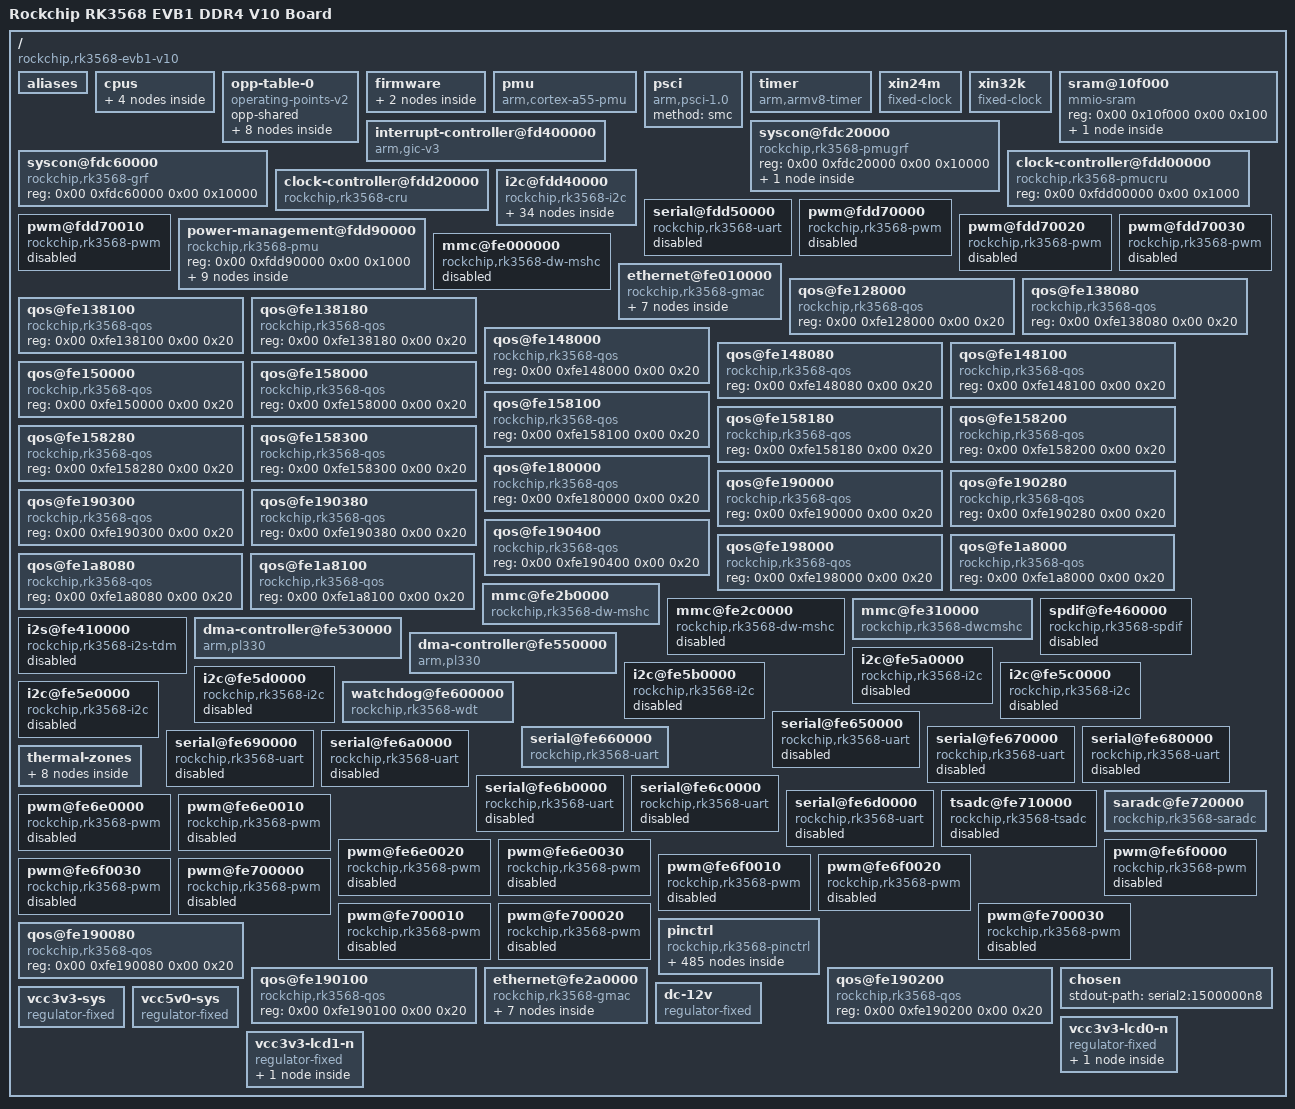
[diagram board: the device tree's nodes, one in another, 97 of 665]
/dts-v1/;

/ {
	interrupt-parent = <0x01>;
	#address-cells = <0x02>;
	#size-cells = <0x02>;
	compatible = "rockchip,rk3568-evb1-v10\0rockchip,rk3568";
	model = "Rockchip RK3568 EVB1 DDR4 V10 Board";

	aliases {
		gpio0 = "/pinctrl/gpio@fdd60000";
		gpio1 = "/pinctrl/gpio@fe740000";
		gpio2 = "/pinctrl/gpio@fe750000";
		gpio3 = "/pinctrl/gpio@fe760000";
		gpio4 = "/pinctrl/gpio@fe770000";
		i2c0 = "/i2c@fdd40000";
		i2c1 = "/i2c@fe5a0000";
		i2c2 = "/i2c@fe5b0000";
		i2c3 = "/i2c@fe5c0000";
		i2c4 = "/i2c@fe5d0000";
		i2c5 = "/i2c@fe5e0000";
		serial0 = "/serial@fdd50000";
		serial1 = "/serial@fe650000";
		serial2 = "/serial@fe660000";
		serial3 = "/serial@fe670000";
		serial4 = "/serial@fe680000";
		serial5 = "/serial@fe690000";
		serial6 = "/serial@fe6a0000";
		serial7 = "/serial@fe6b0000";
		serial8 = "/serial@fe6c0000";
		serial9 = "/serial@fe6d0000";
		ethernet0 = "/ethernet@fe2a0000";
		ethernet1 = "/ethernet@fe010000";
		mmc0 = "/mmc@fe2b0000";
		mmc1 = "/mmc@fe310000";
	};

	cpus {
		#address-cells = <0x02>;
		#size-cells = <0x00>;

		cpu@0 {
			device_type = "cpu";
			compatible = "arm,cortex-a55";
			reg = <0x00 0x00>;
			clocks = <0x02 0x00>;
			#cooling-cells = <0x02>;
			enable-method = "psci";
			operating-points-v2 = <0x03>;
			phandle = <0x05>;
		};

		cpu@100 {
			device_type = "cpu";
			compatible = "arm,cortex-a55";
			reg = <0x00 0x100>;
			#cooling-cells = <0x02>;
			enable-method = "psci";
			operating-points-v2 = <0x03>;
			phandle = <0x06>;
		};

		cpu@200 {
			device_type = "cpu";
			compatible = "arm,cortex-a55";
			reg = <0x00 0x200>;
			#cooling-cells = <0x02>;
			enable-method = "psci";
			operating-points-v2 = <0x03>;
			phandle = <0x07>;
		};

		cpu@300 {
			device_type = "cpu";
			compatible = "arm,cortex-a55";
			reg = <0x00 0x300>;
			#cooling-cells = <0x02>;
			enable-method = "psci";
			operating-points-v2 = <0x03>;
			phandle = <0x08>;
		};
	};

	opp-table-0 {
		compatible = "operating-points-v2";
		opp-shared;
		phandle = <0x03>;

		opp-408000000 {
			opp-hz = <0x00 0x18519600>;
			opp-microvolt = <0xdbba0 0xdbba0 0x118c30>;
			clock-latency-ns = <0x9c40>;
		};

		opp-600000000 {
			opp-hz = <0x00 0x23c34600>;
			opp-microvolt = <0xdbba0 0xdbba0 0x118c30>;
		};

		opp-816000000 {
			opp-hz = <0x00 0x30a32c00>;
			opp-microvolt = <0xdbba0 0xdbba0 0x118c30>;
			opp-suspend;
		};

		opp-1104000000 {
			opp-hz = <0x00 0x41cdb400>;
			opp-microvolt = <0xdbba0 0xdbba0 0x118c30>;
		};

		opp-1416000000 {
			opp-hz = <0x00 0x54667200>;
			opp-microvolt = <0xdbba0 0xdbba0 0x118c30>;
		};

		opp-1608000000 {
			opp-hz = <0x00 0x5fd82200>;
			opp-microvolt = <0xee098 0xee098 0x118c30>;
		};

		opp-1800000000 {
			opp-hz = <0x00 0x6b49d200>;
			opp-microvolt = <0x100590 0x100590 0x118c30>;
		};

		opp-1992000000 {
			opp-hz = <0x00 0x76bb8200>;
			opp-microvolt = <0x118c30 0x118c30 0x118c30>;
		};
	};

	firmware {

		scmi {
			compatible = "arm,scmi-smc";
			arm,smc-id = <0x82000010>;
			shmem = <0x04>;
			#address-cells = <0x01>;
			#size-cells = <0x00>;
			phandle = <0x89>;

			protocol@14 {
				reg = <0x14>;
				#clock-cells = <0x01>;
				phandle = <0x02>;
			};
		};
	};

	pmu {
		compatible = "arm,cortex-a55-pmu";
		interrupts = <0x00 0xe4 0x04 0x00 0xe5 0x04 0x00 0xe6 0x04 0x00 0xe7 0x04>;
		interrupt-affinity = <0x05 0x06 0x07 0x08>;
	};

	psci {
		compatible = "arm,psci-1.0";
		method = "smc";
	};

	timer {
		compatible = "arm,armv8-timer";
		interrupts = <0x01 0x0d 0x04 0x01 0x0e 0x04 0x01 0x0b 0x04 0x01 0x0a 0x04>;
		arm,no-tick-in-suspend;
	};

	xin24m {
		compatible = "fixed-clock";
		clock-frequency = <0x16e3600>;
		clock-output-names = "xin24m";
		#clock-cells = <0x00>;
		phandle = <0x8a>;
	};

	xin32k {
		compatible = "fixed-clock";
		clock-frequency = <0x8000>;
		clock-output-names = "xin32k";
		pinctrl-0 = <0x09>;
		pinctrl-names = "default";
		#clock-cells = <0x00>;
		phandle = <0x8b>;
	};

	sram@10f000 {
		compatible = "mmio-sram";
		reg = <0x00 0x10f000 0x00 0x100>;
		#address-cells = <0x01>;
		#size-cells = <0x01>;
		ranges = <0x00 0x00 0x10f000 0x100>;

		sram@0 {
			compatible = "arm,scmi-shmem";
			reg = <0x00 0x100>;
			phandle = <0x04>;
		};
	};

	interrupt-controller@fd400000 {
		compatible = "arm,gic-v3";
		reg = <0x00 0xfd400000 0x00 0x10000 0x00 0xfd460000 0x00 0x80000>;
		interrupts = <0x01 0x09 0x04>;
		interrupt-controller;
		#interrupt-cells = <0x03>;
		mbi-alias = <0x00 0xfd410000>;
		mbi-ranges = <0x128 0x18>;
		msi-controller;
		phandle = <0x01>;
	};

	syscon@fdc20000 {
		compatible = "rockchip,rk3568-pmugrf\0syscon\0simple-mfd";
		reg = <0x00 0xfdc20000 0x00 0x10000>;
		phandle = <0x76>;

		io-domains {
			compatible = "rockchip,rk3568-pmu-io-voltage-domain";
			status = "okay";
			pmuio1-supply = <0x0a>;
			pmuio2-supply = <0x0a>;
			vccio1-supply = <0x0b>;
			vccio2-supply = <0x0c>;
			vccio3-supply = <0x0d>;
			vccio4-supply = <0x0c>;
			vccio5-supply = <0x0e>;
			vccio6-supply = <0x0c>;
			vccio7-supply = <0x0e>;
			phandle = <0x8c>;
		};
	};

	syscon@fdc60000 {
		compatible = "rockchip,rk3568-grf\0syscon\0simple-mfd";
		reg = <0x00 0xfdc60000 0x00 0x10000>;
		phandle = <0x11>;
	};

	clock-controller@fdd00000 {
		compatible = "rockchip,rk3568-pmucru";
		reg = <0x00 0xfdd00000 0x00 0x1000>;
		#clock-cells = <0x01>;
		#reset-cells = <0x01>;
		phandle = <0x10>;
	};

	clock-controller@fdd20000 {
		compatible = "rockchip,rk3568-cru";
		reg = <0x00 0xfdd20000 0x00 0x1000>;
		#clock-cells = <0x01>;
		#reset-cells = <0x01>;
		assigned-clocks = <0x0f 0x04 0x10 0x01>;
		assigned-clock-rates = <0x47868c00 0xbebc200>;
		rockchip,grf = <0x11>;
		phandle = <0x0f>;
	};

	i2c@fdd40000 {
		compatible = "rockchip,rk3568-i2c\0rockchip,rk3399-i2c";
		reg = <0x00 0xfdd40000 0x00 0x1000>;
		interrupts = <0x00 0x2e 0x04>;
		clocks = <0x10 0x07 0x10 0x2d>;
		clock-names = "i2c\0pclk";
		pinctrl-0 = <0x12>;
		pinctrl-names = "default";
		#address-cells = <0x01>;
		#size-cells = <0x00>;
		status = "okay";
		phandle = <0x8d>;

		pmic@20 {
			compatible = "rockchip,rk809";
			reg = <0x20>;
			interrupt-parent = <0x13>;
			interrupts = <0x03 0x08>;
			#clock-cells = <0x01>;
			pinctrl-names = "default";
			pinctrl-0 = <0x14>;
			rockchip,system-power-controller;
			vcc1-supply = <0x15>;
			vcc2-supply = <0x15>;
			vcc3-supply = <0x15>;
			vcc4-supply = <0x15>;
			vcc5-supply = <0x15>;
			vcc6-supply = <0x15>;
			vcc7-supply = <0x15>;
			vcc8-supply = <0x15>;
			vcc9-supply = <0x15>;
			wakeup-source;
			phandle = <0x8e>;

			regulators {

				DCDC_REG1 {
					regulator-name = "vdd_logic";
					regulator-always-on;
					regulator-boot-on;
					regulator-init-microvolt = <0xdbba0>;
					regulator-initial-mode = <0x02>;
					regulator-min-microvolt = <0x7a120>;
					regulator-max-microvolt = <0x149970>;
					regulator-ramp-delay = <0x1771>;
					phandle = <0x8f>;

					regulator-state-mem {
						regulator-off-in-suspend;
					};
				};

				DCDC_REG2 {
					regulator-name = "vdd_gpu";
					regulator-init-microvolt = <0xdbba0>;
					regulator-initial-mode = <0x02>;
					regulator-min-microvolt = <0x7a120>;
					regulator-max-microvolt = <0x149970>;
					regulator-ramp-delay = <0x1771>;
					phandle = <0x90>;

					regulator-state-mem {
						regulator-off-in-suspend;
					};
				};

				DCDC_REG3 {
					regulator-name = "vcc_ddr";
					regulator-always-on;
					regulator-boot-on;
					regulator-initial-mode = <0x02>;
					phandle = <0x91>;

					regulator-state-mem {
						regulator-on-in-suspend;
					};
				};

				DCDC_REG4 {
					regulator-name = "vdd_npu";
					regulator-init-microvolt = <0xdbba0>;
					regulator-initial-mode = <0x02>;
					regulator-min-microvolt = <0x7a120>;
					regulator-max-microvolt = <0x149970>;
					regulator-ramp-delay = <0x1771>;
					phandle = <0x92>;

					regulator-state-mem {
						regulator-off-in-suspend;
					};
				};

				DCDC_REG5 {
					regulator-name = "vcc_1v8";
					regulator-always-on;
					regulator-boot-on;
					regulator-min-microvolt = <0x1b7740>;
					regulator-max-microvolt = <0x1b7740>;
					phandle = <0x0c>;

					regulator-state-mem {
						regulator-off-in-suspend;
					};
				};

				LDO_REG1 {
					regulator-name = "vdda0v9_image";
					regulator-min-microvolt = <0xdbba0>;
					regulator-max-microvolt = <0xdbba0>;
					phandle = <0x93>;

					regulator-state-mem {
						regulator-off-in-suspend;
					};
				};

				LDO_REG2 {
					regulator-name = "vdda_0v9";
					regulator-always-on;
					regulator-boot-on;
					regulator-min-microvolt = <0xdbba0>;
					regulator-max-microvolt = <0xdbba0>;
					phandle = <0x94>;

					regulator-state-mem {
						regulator-off-in-suspend;
					};
				};

				LDO_REG3 {
					regulator-name = "vdda0v9_pmu";
					regulator-always-on;
					regulator-boot-on;
					regulator-min-microvolt = <0xdbba0>;
					regulator-max-microvolt = <0xdbba0>;
					phandle = <0x95>;

					regulator-state-mem {
						regulator-on-in-suspend;
						regulator-suspend-microvolt = <0xdbba0>;
					};
				};

				LDO_REG4 {
					regulator-name = "vccio_acodec";
					regulator-min-microvolt = <0x325aa0>;
					regulator-max-microvolt = <0x325aa0>;
					phandle = <0x0b>;

					regulator-state-mem {
						regulator-off-in-suspend;
					};
				};

				LDO_REG5 {
					regulator-name = "vccio_sd";
					regulator-min-microvolt = <0x1b7740>;
					regulator-max-microvolt = <0x325aa0>;
					phandle = <0x0d>;

					regulator-state-mem {
						regulator-off-in-suspend;
					};
				};

				LDO_REG6 {
					regulator-name = "vcc3v3_pmu";
					regulator-always-on;
					regulator-boot-on;
					regulator-min-microvolt = <0x325aa0>;
					regulator-max-microvolt = <0x325aa0>;
					phandle = <0x0a>;

					regulator-state-mem {
						regulator-on-in-suspend;
						regulator-suspend-microvolt = <0x325aa0>;
					};
				};

				LDO_REG7 {
					regulator-name = "vcca_1v8";
					regulator-always-on;
					regulator-boot-on;
					regulator-min-microvolt = <0x1b7740>;
					regulator-max-microvolt = <0x1b7740>;
					phandle = <0x69>;

					regulator-state-mem {
						regulator-off-in-suspend;
					};
				};

				LDO_REG8 {
					regulator-name = "vcca1v8_pmu";
					regulator-always-on;
					regulator-boot-on;
					regulator-min-microvolt = <0x1b7740>;
					regulator-max-microvolt = <0x1b7740>;
					phandle = <0x96>;

					regulator-state-mem {
						regulator-on-in-suspend;
						regulator-suspend-microvolt = <0x1b7740>;
					};
				};

				LDO_REG9 {
					regulator-name = "vcca1v8_image";
					regulator-min-microvolt = <0x1b7740>;
					regulator-max-microvolt = <0x1b7740>;
					phandle = <0x97>;

					regulator-state-mem {
						regulator-off-in-suspend;
					};
				};

				SWITCH_REG1 {
					regulator-name = "vcc_3v3";
					regulator-always-on;
					regulator-boot-on;
					phandle = <0x0e>;

					regulator-state-mem {
						regulator-off-in-suspend;
					};
				};

				SWITCH_REG2 {
					regulator-name = "vcc3v3_sd";
					phandle = <0x44>;

					regulator-state-mem {
						regulator-off-in-suspend;
					};
				};
			};
		};
	};

	serial@fdd50000 {
		compatible = "rockchip,rk3568-uart\0snps,dw-apb-uart";
		reg = <0x00 0xfdd50000 0x00 0x100>;
		interrupts = <0x00 0x74 0x04>;
		clocks = <0x10 0x0b 0x10 0x2c>;
		clock-names = "baudclk\0apb_pclk";
		dmas = <0x16 0x00 0x16 0x01>;
		pinctrl-0 = <0x17>;
		pinctrl-names = "default";
		reg-io-width = <0x04>;
		reg-shift = <0x02>;
		status = "disabled";
		phandle = <0x98>;
	};

	pwm@fdd70000 {
		compatible = "rockchip,rk3568-pwm\0rockchip,rk3328-pwm";
		reg = <0x00 0xfdd70000 0x00 0x10>;
		clocks = <0x10 0x0d 0x10 0x30>;
		clock-names = "pwm\0pclk";
		pinctrl-0 = <0x18>;
		pinctrl-names = "active";
		#pwm-cells = <0x03>;
		status = "disabled";
		phandle = <0x99>;
	};

	pwm@fdd70010 {
		compatible = "rockchip,rk3568-pwm\0rockchip,rk3328-pwm";
		reg = <0x00 0xfdd70010 0x00 0x10>;
		clocks = <0x10 0x0d 0x10 0x30>;
		clock-names = "pwm\0pclk";
		pinctrl-0 = <0x19>;
		pinctrl-names = "active";
		#pwm-cells = <0x03>;
		status = "disabled";
		phandle = <0x9a>;
	};

	pwm@fdd70020 {
		compatible = "rockchip,rk3568-pwm\0rockchip,rk3328-pwm";
		reg = <0x00 0xfdd70020 0x00 0x10>;
		clocks = <0x10 0x0d 0x10 0x30>;
		clock-names = "pwm\0pclk";
		pinctrl-0 = <0x1a>;
		pinctrl-names = "active";
		#pwm-cells = <0x03>;
		status = "disabled";
		phandle = <0x9b>;
	};

	pwm@fdd70030 {
		compatible = "rockchip,rk3568-pwm\0rockchip,rk3328-pwm";
		reg = <0x00 0xfdd70030 0x00 0x10>;
		clocks = <0x10 0x0d 0x10 0x30>;
		clock-names = "pwm\0pclk";
		pinctrl-0 = <0x1b>;
		pinctrl-names = "active";
		#pwm-cells = <0x03>;
		status = "disabled";
		phandle = <0x9c>;
	};

	power-management@fdd90000 {
		compatible = "rockchip,rk3568-pmu\0syscon\0simple-mfd";
		reg = <0x00 0xfdd90000 0x00 0x1000>;
		phandle = <0x9d>;

		power-controller {
			compatible = "rockchip,rk3568-power-controller";
			#power-domain-cells = <0x01>;
			#address-cells = <0x01>;
			#size-cells = <0x00>;
			phandle = <0x9e>;

			power-domain@7 {
				reg = <0x07>;
				clocks = <0x0f 0x19 0x0f 0x1a>;
				pm_qos = <0x1c>;
				#power-domain-cells = <0x00>;
			};

			power-domain@8 {
				reg = <0x08>;
				clocks = <0x0f 0xcc 0x0f 0xcd>;
				pm_qos = <0x1d 0x1e 0x1f>;
				#power-domain-cells = <0x00>;
			};

			power-domain@9 {
				reg = <0x09>;
				clocks = <0x0f 0xda 0x0f 0xdb 0x0f 0xdc>;
				pm_qos = <0x20 0x21 0x22>;
				#power-domain-cells = <0x00>;
			};

			power-domain@10 {
				reg = <0x0a>;
				clocks = <0x0f 0xf1 0x0f 0xf2>;
				pm_qos = <0x23 0x24 0x25 0x26 0x27 0x28>;
				#power-domain-cells = <0x00>;
			};

			power-domain@11 {
				reg = <0x0b>;
				clocks = <0x0f 0xed>;
				pm_qos = <0x29>;
				#power-domain-cells = <0x00>;
			};

			power-domain@13 {
				clocks = <0x0f 0x107>;
				reg = <0x0d>;
				pm_qos = <0x2a>;
				#power-domain-cells = <0x00>;
			};

			power-domain@14 {
				reg = <0x0e>;
				clocks = <0x0f 0x102>;
				pm_qos = <0x2b 0x2c 0x2d>;
				#power-domain-cells = <0x00>;
			};

			power-domain@15 {
				reg = <0x0f>;
				clocks = <0x0f 0x7f>;
				pm_qos = <0x2e 0x2f 0x30 0x31 0x32 0x33 0x34 0x35>;
				#power-domain-cells = <0x00>;
			};
		};
	};

	mmc@fe000000 {
		compatible = "rockchip,rk3568-dw-mshc\0rockchip,rk3288-dw-mshc";
		reg = <0x00 0xfe000000 0x00 0x4000>;
		interrupts = <0x00 0x64 0x04>;
		clocks = <0x0f 0xc1 0x0f 0xc2 0x0f 0x18e 0x0f 0x18f>;
		clock-names = "biu\0ciu\0ciu-drive\0ciu-sample";
		fifo-depth = <0x100>;
		max-frequency = <0x8f0d180>;
		resets = <0x0f 0xeb>;
		reset-names = "reset";
		status = "disabled";
		phandle = <0x9f>;
	};

	ethernet@fe010000 {
		compatible = "rockchip,rk3568-gmac\0snps,dwmac-4.20a";
		reg = <0x00 0xfe010000 0x00 0x10000>;
		interrupts = <0x00 0x20 0x04 0x00 0x1d 0x04>;
		interrupt-names = "macirq\0eth_wake_irq";
		clocks = <0x0f 0x186 0x0f 0x189 0x0f 0x189 0x0f 0xc7 0x0f 0xc3 0x0f 0xc4 0x0f 0x189 0x0f 0xc8>;
		clock-names = "stmmaceth\0mac_clk_rx\0mac_clk_tx\0clk_mac_refout\0aclk_mac\0pclk_mac\0clk_mac_speed\0ptp_ref";
		resets = <0x0f 0xec>;
		reset-names = "stmmaceth";
		rockchip,grf = <0x11>;
		snps,axi-config = <0x36>;
		snps,mixed-burst;
		snps,mtl-rx-config = <0x37>;
		snps,mtl-tx-config = <0x38>;
		snps,tso;
		status = "okay";
		assigned-clocks = <0x0f 0x189 0x0f 0x186>;
		assigned-clock-parents = <0x0f 0x187>;
		assigned-clock-rates = <0x00 0x7735940>;
		clock_in_out = "output";
		phy-handle = <0x39>;
		phy-mode = "rgmii-id";
		pinctrl-names = "default";
		pinctrl-0 = <0x3a 0x3b 0x3c 0x3d 0x3e>;
		phandle = <0xa0>;

		mdio {
			compatible = "snps,dwmac-mdio";
			#address-cells = <0x01>;
			#size-cells = <0x00>;
			phandle = <0xa1>;

			ethernet-phy@0 {
				compatible = "ethernet-phy-ieee802.3-c22";
				reg = <0x00>;
				reset-assert-us = <0x4e20>;
				reset-deassert-us = <0x186a0>;
				reset-gpios = <0x3f 0x19 0x01>;
				phandle = <0x39>;
			};
		};

		stmmac-axi-config {
			snps,blen = <0x00 0x00 0x00 0x00 0x10 0x08 0x04>;
			snps,rd_osr_lmt = <0x08>;
			snps,wr_osr_lmt = <0x04>;
			phandle = <0x36>;
		};

		rx-queues-config {
			snps,rx-queues-to-use = <0x01>;
			phandle = <0x37>;

			queue0 {
			};
		};

		tx-queues-config {
			snps,tx-queues-to-use = <0x01>;
			phandle = <0x38>;

			queue0 {
			};
		};
	};

	qos@fe128000 {
		compatible = "rockchip,rk3568-qos\0syscon";
		reg = <0x00 0xfe128000 0x00 0x20>;
		phandle = <0x1c>;
	};

	qos@fe138080 {
		compatible = "rockchip,rk3568-qos\0syscon";
		reg = <0x00 0xfe138080 0x00 0x20>;
		phandle = <0x2b>;
	};

	qos@fe138100 {
		compatible = "rockchip,rk3568-qos\0syscon";
		reg = <0x00 0xfe138100 0x00 0x20>;
		phandle = <0x2c>;
	};

	qos@fe138180 {
		compatible = "rockchip,rk3568-qos\0syscon";
		reg = <0x00 0xfe138180 0x00 0x20>;
		phandle = <0x2d>;
	};

	qos@fe148000 {
		compatible = "rockchip,rk3568-qos\0syscon";
		reg = <0x00 0xfe148000 0x00 0x20>;
		phandle = <0x1d>;
	};

	qos@fe148080 {
		compatible = "rockchip,rk3568-qos\0syscon";
		reg = <0x00 0xfe148080 0x00 0x20>;
		phandle = <0x1e>;
	};

	qos@fe148100 {
		compatible = "rockchip,rk3568-qos\0syscon";
		reg = <0x00 0xfe148100 0x00 0x20>;
		phandle = <0x1f>;
	};

	qos@fe150000 {
		compatible = "rockchip,rk3568-qos\0syscon";
		reg = <0x00 0xfe150000 0x00 0x20>;
		phandle = <0x29>;
	};

	qos@fe158000 {
		compatible = "rockchip,rk3568-qos\0syscon";
		reg = <0x00 0xfe158000 0x00 0x20>;
		phandle = <0x23>;
	};

	qos@fe158100 {
		compatible = "rockchip,rk3568-qos\0syscon";
		reg = <0x00 0xfe158100 0x00 0x20>;
		phandle = <0x24>;
	};

	qos@fe158180 {
		compatible = "rockchip,rk3568-qos\0syscon";
		reg = <0x00 0xfe158180 0x00 0x20>;
		phandle = <0x25>;
	};

	qos@fe158200 {
		compatible = "rockchip,rk3568-qos\0syscon";
		reg = <0x00 0xfe158200 0x00 0x20>;
		phandle = <0x26>;
	};

	qos@fe158280 {
		compatible = "rockchip,rk3568-qos\0syscon";
		reg = <0x00 0xfe158280 0x00 0x20>;
		phandle = <0x27>;
	};

	qos@fe158300 {
		compatible = "rockchip,rk3568-qos\0syscon";
		reg = <0x00 0xfe158300 0x00 0x20>;
		phandle = <0x28>;
	};

	qos@fe180000 {
		compatible = "rockchip,rk3568-qos\0syscon";
		reg = <0x00 0xfe180000 0x00 0x20>;
		phandle = <0xa2>;
	};

	qos@fe190000 {
		compatible = "rockchip,rk3568-qos\0syscon";
		reg = <0x00 0xfe190000 0x00 0x20>;
		phandle = <0x2e>;
	};

	qos@fe190280 {
		compatible = "rockchip,rk3568-qos\0syscon";
		reg = <0x00 0xfe190280 0x00 0x20>;
		phandle = <0x32>;
	};

	qos@fe190300 {
		compatible = "rockchip,rk3568-qos\0syscon";
		reg = <0x00 0xfe190300 0x00 0x20>;
		phandle = <0x33>;
	};

	qos@fe190380 {
		compatible = "rockchip,rk3568-qos\0syscon";
		reg = <0x00 0xfe190380 0x00 0x20>;
		phandle = <0x34>;
	};

	qos@fe190400 {
		compatible = "rockchip,rk3568-qos\0syscon";
		reg = <0x00 0xfe190400 0x00 0x20>;
		phandle = <0x35>;
	};

	qos@fe198000 {
		compatible = "rockchip,rk3568-qos\0syscon";
		reg = <0x00 0xfe198000 0x00 0x20>;
		phandle = <0x2a>;
	};

	qos@fe1a8000 {
		compatible = "rockchip,rk3568-qos\0syscon";
		reg = <0x00 0xfe1a8000 0x00 0x20>;
		phandle = <0x20>;
	};

	qos@fe1a8080 {
		compatible = "rockchip,rk3568-qos\0syscon";
		reg = <0x00 0xfe1a8080 0x00 0x20>;
		phandle = <0x21>;
	};

	qos@fe1a8100 {
		compatible = "rockchip,rk3568-qos\0syscon";
		reg = <0x00 0xfe1a8100 0x00 0x20>;
		phandle = <0x22>;
	};

	mmc@fe2b0000 {
		compatible = "rockchip,rk3568-dw-mshc\0rockchip,rk3288-dw-mshc";
		reg = <0x00 0xfe2b0000 0x00 0x4000>;
		interrupts = <0x00 0x62 0x04>;
		clocks = <0x0f 0xb0 0x0f 0xb1 0x0f 0x18a 0x0f 0x18b>;
		clock-names = "biu\0ciu\0ciu-drive\0ciu-sample";
		fifo-depth = <0x100>;
		max-frequency = <0x8f0d180>;
		resets = <0x0f 0xd4>;
		reset-names = "reset";
		status = "okay";
		bus-width = <0x04>;
		cap-sd-highspeed;
		cd-gpios = <0x13 0x04 0x01>;
		disable-wp;
		pinctrl-names = "default";
		pinctrl-0 = <0x40 0x41 0x42 0x43>;
		sd-uhs-sdr104;
		vmmc-supply = <0x44>;
		vqmmc-supply = <0x0d>;
		phandle = <0xa3>;
	};

	mmc@fe2c0000 {
		compatible = "rockchip,rk3568-dw-mshc\0rockchip,rk3288-dw-mshc";
		reg = <0x00 0xfe2c0000 0x00 0x4000>;
		interrupts = <0x00 0x63 0x04>;
		clocks = <0x0f 0xb2 0x0f 0xb3 0x0f 0x18c 0x0f 0x18d>;
		clock-names = "biu\0ciu\0ciu-drive\0ciu-sample";
		fifo-depth = <0x100>;
		max-frequency = <0x8f0d180>;
		resets = <0x0f 0xd6>;
		reset-names = "reset";
		status = "disabled";
		phandle = <0xa4>;
	};

	mmc@fe310000 {
		compatible = "rockchip,rk3568-dwcmshc";
		reg = <0x00 0xfe310000 0x00 0x10000>;
		interrupts = <0x00 0x13 0x04>;
		assigned-clocks = <0x0f 0x7b 0x0f 0x7d>;
		assigned-clock-rates = <0xbebc200 0x16e3600>;
		clocks = <0x0f 0x7c 0x0f 0x7a 0x0f 0x79 0x0f 0x7b 0x0f 0x7d>;
		clock-names = "core\0bus\0axi\0block\0timer";
		status = "okay";
		bus-width = <0x08>;
		max-frequency = <0xbebc200>;
		non-removable;
		pinctrl-names = "default";
		pinctrl-0 = <0x45 0x46 0x47 0x48>;
		phandle = <0xa5>;
	};

	spdif@fe460000 {
		compatible = "rockchip,rk3568-spdif";
		reg = <0x00 0xfe460000 0x00 0x1000>;
		interrupts = <0x00 0x66 0x04>;
		clock-names = "mclk\0hclk";
		clocks = <0x0f 0x5f 0x0f 0x5c>;
		dmas = <0x49 0x01>;
		dma-names = "tx";
		pinctrl-names = "default";
		pinctrl-0 = <0x4a>;
		#sound-dai-cells = <0x00>;
		status = "disabled";
		phandle = <0xa6>;
	};

	i2s@fe410000 {
		compatible = "rockchip,rk3568-i2s-tdm";
		reg = <0x00 0xfe410000 0x00 0x1000>;
		interrupts = <0x00 0x35 0x04>;
		assigned-clocks = <0x0f 0x45 0x0f 0x49>;
		assigned-clock-rates = <0x46cf7100 0x46cf7100>;
		clocks = <0x0f 0x47 0x0f 0x4b 0x0f 0x3a>;
		clock-names = "mclk_tx\0mclk_rx\0hclk";
		dmas = <0x49 0x03 0x49 0x02>;
		dma-names = "rx\0tx";
		resets = <0x0f 0x52 0x0f 0x53>;
		reset-names = "tx-m\0rx-m";
		rockchip,grf = <0x11>;
		pinctrl-names = "default";
		pinctrl-0 = <0x4b 0x4c 0x4d 0x4e 0x4f 0x50 0x51 0x52 0x53 0x54 0x55 0x56>;
		#sound-dai-cells = <0x00>;
		status = "disabled";
		phandle = <0xa7>;
	};

	dma-controller@fe530000 {
		compatible = "arm,pl330\0arm,primecell";
		reg = <0x00 0xfe530000 0x00 0x4000>;
		interrupts = <0x00 0x0e 0x04 0x00 0x0d 0x04>;
		arm,pl330-periph-burst;
		clocks = <0x0f 0x10d>;
		clock-names = "apb_pclk";
		#dma-cells = <0x01>;
		phandle = <0x16>;
	};

	dma-controller@fe550000 {
		compatible = "arm,pl330\0arm,primecell";
		reg = <0x00 0xfe550000 0x00 0x4000>;
		interrupts = <0x00 0x10 0x04 0x00 0x0f 0x04>;
		arm,pl330-periph-burst;
		clocks = <0x0f 0x10d>;
		clock-names = "apb_pclk";
		#dma-cells = <0x01>;
		phandle = <0x49>;
	};

	i2c@fe5a0000 {
		compatible = "rockchip,rk3568-i2c\0rockchip,rk3399-i2c";
		reg = <0x00 0xfe5a0000 0x00 0x1000>;
		interrupts = <0x00 0x2f 0x04>;
		clocks = <0x0f 0x148 0x0f 0x147>;
		clock-names = "i2c\0pclk";
		pinctrl-0 = <0x57>;
		pinctrl-names = "default";
		#address-cells = <0x01>;
		#size-cells = <0x00>;
		status = "disabled";
		phandle = <0xa8>;
	};

	i2c@fe5b0000 {
		compatible = "rockchip,rk3568-i2c\0rockchip,rk3399-i2c";
		reg = <0x00 0xfe5b0000 0x00 0x1000>;
		interrupts = <0x00 0x30 0x04>;
		clocks = <0x0f 0x14a 0x0f 0x149>;
		clock-names = "i2c\0pclk";
		pinctrl-0 = <0x58>;
		pinctrl-names = "default";
		#address-cells = <0x01>;
		#size-cells = <0x00>;
		status = "disabled";
		phandle = <0xa9>;
	};

	i2c@fe5c0000 {
		compatible = "rockchip,rk3568-i2c\0rockchip,rk3399-i2c";
		reg = <0x00 0xfe5c0000 0x00 0x1000>;
		interrupts = <0x00 0x31 0x04>;
		clocks = <0x0f 0x14c 0x0f 0x14b>;
		clock-names = "i2c\0pclk";
		pinctrl-0 = <0x59>;
		pinctrl-names = "default";
		#address-cells = <0x01>;
		#size-cells = <0x00>;
		status = "disabled";
		phandle = <0xaa>;
	};

	i2c@fe5d0000 {
		compatible = "rockchip,rk3568-i2c\0rockchip,rk3399-i2c";
		reg = <0x00 0xfe5d0000 0x00 0x1000>;
		interrupts = <0x00 0x32 0x04>;
		clocks = <0x0f 0x14e 0x0f 0x14d>;
		clock-names = "i2c\0pclk";
		pinctrl-0 = <0x5a>;
		pinctrl-names = "default";
		#address-cells = <0x01>;
		#size-cells = <0x00>;
		status = "disabled";
		phandle = <0xab>;
	};

	i2c@fe5e0000 {
		compatible = "rockchip,rk3568-i2c\0rockchip,rk3399-i2c";
		reg = <0x00 0xfe5e0000 0x00 0x1000>;
		interrupts = <0x00 0x33 0x04>;
		clocks = <0x0f 0x150 0x0f 0x14f>;
		clock-names = "i2c\0pclk";
		pinctrl-0 = <0x5b>;
		pinctrl-names = "default";
		#address-cells = <0x01>;
		#size-cells = <0x00>;
		status = "disabled";
		phandle = <0xac>;
	};

	watchdog@fe600000 {
		compatible = "rockchip,rk3568-wdt\0snps,dw-wdt";
		reg = <0x00 0xfe600000 0x00 0x100>;
		interrupts = <0x00 0x95 0x04>;
		clocks = <0x0f 0x116 0x0f 0x115>;
		clock-names = "tclk\0pclk";
		phandle = <0xad>;
	};

	serial@fe650000 {
		compatible = "rockchip,rk3568-uart\0snps,dw-apb-uart";
		reg = <0x00 0xfe650000 0x00 0x100>;
		interrupts = <0x00 0x75 0x04>;
		clocks = <0x0f 0x11f 0x0f 0x11c>;
		clock-names = "baudclk\0apb_pclk";
		dmas = <0x16 0x02 0x16 0x03>;
		pinctrl-0 = <0x5c>;
		pinctrl-names = "default";
		reg-io-width = <0x04>;
		reg-shift = <0x02>;
		status = "disabled";
		phandle = <0xae>;
	};

	serial@fe660000 {
		compatible = "rockchip,rk3568-uart\0snps,dw-apb-uart";
		reg = <0x00 0xfe660000 0x00 0x100>;
		interrupts = <0x00 0x76 0x04>;
		clocks = <0x0f 0x123 0x0f 0x120>;
		clock-names = "baudclk\0apb_pclk";
		dmas = <0x16 0x04 0x16 0x05>;
		pinctrl-0 = <0x5d>;
		pinctrl-names = "default";
		reg-io-width = <0x04>;
		reg-shift = <0x02>;
		status = "okay";
		phandle = <0xaf>;
	};

	serial@fe670000 {
		compatible = "rockchip,rk3568-uart\0snps,dw-apb-uart";
		reg = <0x00 0xfe670000 0x00 0x100>;
		interrupts = <0x00 0x77 0x04>;
		clocks = <0x0f 0x127 0x0f 0x124>;
		clock-names = "baudclk\0apb_pclk";
		dmas = <0x16 0x06 0x16 0x07>;
		pinctrl-0 = <0x5e>;
		pinctrl-names = "default";
		reg-io-width = <0x04>;
		reg-shift = <0x02>;
		status = "disabled";
		phandle = <0xb0>;
	};

	serial@fe680000 {
		compatible = "rockchip,rk3568-uart\0snps,dw-apb-uart";
		reg = <0x00 0xfe680000 0x00 0x100>;
		interrupts = <0x00 0x78 0x04>;
		clocks = <0x0f 0x12b 0x0f 0x128>;
		clock-names = "baudclk\0apb_pclk";
		dmas = <0x16 0x08 0x16 0x09>;
		pinctrl-0 = <0x5f>;
		pinctrl-names = "default";
		reg-io-width = <0x04>;
		reg-shift = <0x02>;
		status = "disabled";
		phandle = <0xb1>;
	};

	serial@fe690000 {
		compatible = "rockchip,rk3568-uart\0snps,dw-apb-uart";
		reg = <0x00 0xfe690000 0x00 0x100>;
		interrupts = <0x00 0x79 0x04>;
		clocks = <0x0f 0x12f 0x0f 0x12c>;
		clock-names = "baudclk\0apb_pclk";
		dmas = <0x16 0x0a 0x16 0x0b>;
		pinctrl-0 = <0x60>;
		pinctrl-names = "default";
		reg-io-width = <0x04>;
		reg-shift = <0x02>;
		status = "disabled";
		phandle = <0xb2>;
	};

	serial@fe6a0000 {
		compatible = "rockchip,rk3568-uart\0snps,dw-apb-uart";
		reg = <0x00 0xfe6a0000 0x00 0x100>;
		interrupts = <0x00 0x7a 0x04>;
		clocks = <0x0f 0x133 0x0f 0x130>;
		clock-names = "baudclk\0apb_pclk";
		dmas = <0x16 0x0c 0x16 0x0d>;
		pinctrl-0 = <0x61>;
		pinctrl-names = "default";
		reg-io-width = <0x04>;
		reg-shift = <0x02>;
		status = "disabled";
		phandle = <0xb3>;
	};

	serial@fe6b0000 {
		compatible = "rockchip,rk3568-uart\0snps,dw-apb-uart";
		reg = <0x00 0xfe6b0000 0x00 0x100>;
		interrupts = <0x00 0x7b 0x04>;
		clocks = <0x0f 0x137 0x0f 0x134>;
		clock-names = "baudclk\0apb_pclk";
		dmas = <0x16 0x0e 0x16 0x0f>;
		pinctrl-0 = <0x62>;
		pinctrl-names = "default";
		reg-io-width = <0x04>;
		reg-shift = <0x02>;
		status = "disabled";
		phandle = <0xb4>;
	};

	serial@fe6c0000 {
		compatible = "rockchip,rk3568-uart\0snps,dw-apb-uart";
		reg = <0x00 0xfe6c0000 0x00 0x100>;
		interrupts = <0x00 0x7c 0x04>;
		clocks = <0x0f 0x13b 0x0f 0x138>;
		clock-names = "baudclk\0apb_pclk";
		dmas = <0x16 0x10 0x16 0x11>;
		pinctrl-0 = <0x63>;
		pinctrl-names = "default";
		reg-io-width = <0x04>;
		reg-shift = <0x02>;
		status = "disabled";
		phandle = <0xb5>;
	};

	serial@fe6d0000 {
		compatible = "rockchip,rk3568-uart\0snps,dw-apb-uart";
		reg = <0x00 0xfe6d0000 0x00 0x100>;
		interrupts = <0x00 0x7d 0x04>;
		clocks = <0x0f 0x13f 0x0f 0x13c>;
		clock-names = "baudclk\0apb_pclk";
		dmas = <0x16 0x12 0x16 0x13>;
		pinctrl-0 = <0x64>;
		pinctrl-names = "default";
		reg-io-width = <0x04>;
		reg-shift = <0x02>;
		status = "disabled";
		phandle = <0xb6>;
	};

	thermal-zones {
		phandle = <0xb7>;

		cpu-thermal {
			polling-delay-passive = <0x64>;
			polling-delay = <0x3e8>;
			thermal-sensors = <0x65 0x00>;
			phandle = <0xb8>;

			trips {

				cpu_alert0 {
					temperature = <0x11170>;
					hysteresis = <0x7d0>;
					type = "passive";
					phandle = <0x66>;
				};

				cpu_alert1 {
					temperature = <0x124f8>;
					hysteresis = <0x7d0>;
					type = "passive";
					phandle = <0xb9>;
				};

				cpu_crit {
					temperature = <0x17318>;
					hysteresis = <0x7d0>;
					type = "critical";
					phandle = <0xba>;
				};
			};

			cooling-maps {

				map0 {
					trip = <0x66>;
					cooling-device = <0x05 0xffffffff 0xffffffff 0x06 0xffffffff 0xffffffff 0x07 0xffffffff 0xffffffff 0x08 0xffffffff 0xffffffff>;
				};
			};
		};

		gpu-thermal {
			polling-delay-passive = <0x14>;
			polling-delay = <0x3e8>;
			thermal-sensors = <0x65 0x01>;
			phandle = <0xbb>;
		};
	};

	tsadc@fe710000 {
		compatible = "rockchip,rk3568-tsadc";
		reg = <0x00 0xfe710000 0x00 0x100>;
		interrupts = <0x00 0x73 0x04>;
		assigned-clocks = <0x0f 0x110 0x0f 0x111>;
		assigned-clock-rates = <0x1036640 0xaae60>;
		clocks = <0x0f 0x111 0x0f 0x10f>;
		clock-names = "tsadc\0apb_pclk";
		resets = <0x0f 0x181 0x0f 0x182 0x0f 0x1d7>;
		rockchip,grf = <0x11>;
		rockchip,hw-tshut-temp = <0x17318>;
		pinctrl-names = "init\0default\0sleep";
		pinctrl-0 = <0x67>;
		pinctrl-1 = <0x68>;
		pinctrl-2 = <0x67>;
		#thermal-sensor-cells = <0x01>;
		status = "disabled";
		phandle = <0x65>;
	};

	saradc@fe720000 {
		compatible = "rockchip,rk3568-saradc\0rockchip,rk3399-saradc";
		reg = <0x00 0xfe720000 0x00 0x100>;
		interrupts = <0x00 0x5d 0x04>;
		clocks = <0x0f 0x113 0x0f 0x112>;
		clock-names = "saradc\0apb_pclk";
		resets = <0x0f 0x180>;
		reset-names = "saradc-apb";
		#io-channel-cells = <0x01>;
		status = "okay";
		vref-supply = <0x69>;
		phandle = <0xbc>;
	};

	pwm@fe6e0000 {
		compatible = "rockchip,rk3568-pwm\0rockchip,rk3328-pwm";
		reg = <0x00 0xfe6e0000 0x00 0x10>;
		clocks = <0x0f 0x15a 0x0f 0x159>;
		clock-names = "pwm\0pclk";
		pinctrl-0 = <0x6a>;
		pinctrl-names = "active";
		#pwm-cells = <0x03>;
		status = "disabled";
		phandle = <0xbd>;
	};

	pwm@fe6e0010 {
		compatible = "rockchip,rk3568-pwm\0rockchip,rk3328-pwm";
		reg = <0x00 0xfe6e0010 0x00 0x10>;
		clocks = <0x0f 0x15a 0x0f 0x159>;
		clock-names = "pwm\0pclk";
		pinctrl-0 = <0x6b>;
		pinctrl-names = "active";
		#pwm-cells = <0x03>;
		status = "disabled";
		phandle = <0xbe>;
	};

	pwm@fe6e0020 {
		compatible = "rockchip,rk3568-pwm\0rockchip,rk3328-pwm";
		reg = <0x00 0xfe6e0020 0x00 0x10>;
		clocks = <0x0f 0x15a 0x0f 0x159>;
		clock-names = "pwm\0pclk";
		pinctrl-0 = <0x6c>;
		pinctrl-names = "active";
		#pwm-cells = <0x03>;
		status = "disabled";
		phandle = <0xbf>;
	};

	pwm@fe6e0030 {
		compatible = "rockchip,rk3568-pwm\0rockchip,rk3328-pwm";
		reg = <0x00 0xfe6e0030 0x00 0x10>;
		clocks = <0x0f 0x15a 0x0f 0x159>;
		clock-names = "pwm\0pclk";
		pinctrl-0 = <0x6d>;
		pinctrl-names = "active";
		#pwm-cells = <0x03>;
		status = "disabled";
		phandle = <0xc0>;
	};

	pwm@fe6f0000 {
		compatible = "rockchip,rk3568-pwm\0rockchip,rk3328-pwm";
		reg = <0x00 0xfe6f0000 0x00 0x10>;
		clocks = <0x0f 0x15d 0x0f 0x15c>;
		clock-names = "pwm\0pclk";
		pinctrl-0 = <0x6e>;
		pinctrl-names = "active";
		#pwm-cells = <0x03>;
		status = "disabled";
		phandle = <0xc1>;
	};

	pwm@fe6f0010 {
		compatible = "rockchip,rk3568-pwm\0rockchip,rk3328-pwm";
		reg = <0x00 0xfe6f0010 0x00 0x10>;
		clocks = <0x0f 0x15d 0x0f 0x15c>;
		clock-names = "pwm\0pclk";
		pinctrl-0 = <0x6f>;
		pinctrl-names = "active";
		#pwm-cells = <0x03>;
		status = "disabled";
		phandle = <0xc2>;
	};

	pwm@fe6f0020 {
		compatible = "rockchip,rk3568-pwm\0rockchip,rk3328-pwm";
		reg = <0x00 0xfe6f0020 0x00 0x10>;
		clocks = <0x0f 0x15d 0x0f 0x15c>;
		clock-names = "pwm\0pclk";
		pinctrl-0 = <0x70>;
		pinctrl-names = "active";
		#pwm-cells = <0x03>;
		status = "disabled";
		phandle = <0xc3>;
	};

	pwm@fe6f0030 {
		compatible = "rockchip,rk3568-pwm\0rockchip,rk3328-pwm";
		reg = <0x00 0xfe6f0030 0x00 0x10>;
		clocks = <0x0f 0x15d 0x0f 0x15c>;
		clock-names = "pwm\0pclk";
		pinctrl-0 = <0x71>;
		pinctrl-names = "active";
		#pwm-cells = <0x03>;
		status = "disabled";
		phandle = <0xc4>;
	};

	pwm@fe700000 {
		compatible = "rockchip,rk3568-pwm\0rockchip,rk3328-pwm";
		reg = <0x00 0xfe700000 0x00 0x10>;
		clocks = <0x0f 0x160 0x0f 0x15f>;
		clock-names = "pwm\0pclk";
		pinctrl-0 = <0x72>;
		pinctrl-names = "active";
		#pwm-cells = <0x03>;
		status = "disabled";
		phandle = <0xc5>;
	};

	pwm@fe700010 {
		compatible = "rockchip,rk3568-pwm\0rockchip,rk3328-pwm";
		reg = <0x00 0xfe700010 0x00 0x10>;
		clocks = <0x0f 0x160 0x0f 0x15f>;
		clock-names = "pwm\0pclk";
		pinctrl-0 = <0x73>;
		pinctrl-names = "active";
		#pwm-cells = <0x03>;
		status = "disabled";
		phandle = <0xc6>;
	};

	pwm@fe700020 {
		compatible = "rockchip,rk3568-pwm\0rockchip,rk3328-pwm";
		reg = <0x00 0xfe700020 0x00 0x10>;
		clocks = <0x0f 0x160 0x0f 0x15f>;
		clock-names = "pwm\0pclk";
		pinctrl-0 = <0x74>;
		pinctrl-names = "active";
		#pwm-cells = <0x03>;
		status = "disabled";
		phandle = <0xc7>;
	};

	pwm@fe700030 {
		compatible = "rockchip,rk3568-pwm\0rockchip,rk3328-pwm";
		reg = <0x00 0xfe700030 0x00 0x10>;
		clocks = <0x0f 0x160 0x0f 0x15f>;
		clock-names = "pwm\0pclk";
		pinctrl-0 = <0x75>;
		pinctrl-names = "active";
		#pwm-cells = <0x03>;
		status = "disabled";
		phandle = <0xc8>;
	};

	pinctrl {
		compatible = "rockchip,rk3568-pinctrl";
		rockchip,grf = <0x11>;
		rockchip,pmu = <0x76>;
		#address-cells = <0x02>;
		#size-cells = <0x02>;
		ranges;
		phandle = <0xc9>;

		gpio@fdd60000 {
			compatible = "rockchip,gpio-bank";
			reg = <0x00 0xfdd60000 0x00 0x100>;
			interrupts = <0x00 0x21 0x04>;
			clocks = <0x10 0x2e 0x10 0x0c>;
			gpio-controller;
			#gpio-cells = <0x02>;
			interrupt-controller;
			#interrupt-cells = <0x02>;
			phandle = <0x13>;
		};

		gpio@fe740000 {
			compatible = "rockchip,gpio-bank";
			reg = <0x00 0xfe740000 0x00 0x100>;
			interrupts = <0x00 0x22 0x04>;
			clocks = <0x0f 0x163 0x0f 0x164>;
			gpio-controller;
			#gpio-cells = <0x02>;
			interrupt-controller;
			#interrupt-cells = <0x02>;
			phandle = <0xca>;
		};

		gpio@fe750000 {
			compatible = "rockchip,gpio-bank";
			reg = <0x00 0xfe750000 0x00 0x100>;
			interrupts = <0x00 0x23 0x04>;
			clocks = <0x0f 0x165 0x0f 0x166>;
			gpio-controller;
			#gpio-cells = <0x02>;
			interrupt-controller;
			#interrupt-cells = <0x02>;
			phandle = <0x3f>;
		};

		gpio@fe760000 {
			compatible = "rockchip,gpio-bank";
			reg = <0x00 0xfe760000 0x00 0x100>;
			interrupts = <0x00 0x24 0x04>;
			clocks = <0x0f 0x167 0x0f 0x168>;
			gpio-controller;
			#gpio-cells = <0x02>;
			interrupt-controller;
			#interrupt-cells = <0x02>;
			phandle = <0xcb>;
		};

		gpio@fe770000 {
			compatible = "rockchip,gpio-bank";
			reg = <0x00 0xfe770000 0x00 0x100>;
			interrupts = <0x00 0x25 0x04>;
			clocks = <0x0f 0x169 0x0f 0x16a>;
			gpio-controller;
			#gpio-cells = <0x02>;
			interrupt-controller;
			#interrupt-cells = <0x02>;
			phandle = <0xcc>;
		};

		pcfg-pull-up {
			bias-pull-up;
			phandle = <0x79>;
		};

		pcfg-pull-down {
			bias-pull-down;
			phandle = <0xcd>;
		};

		pcfg-pull-none {
			bias-disable;
			phandle = <0x77>;
		};

		pcfg-pull-none-drv-level-0 {
			bias-disable;
			drive-strength = <0x00>;
			phandle = <0xce>;
		};

		pcfg-pull-none-drv-level-1 {
			bias-disable;
			drive-strength = <0x01>;
			phandle = <0x7b>;
		};

		pcfg-pull-none-drv-level-2 {
			bias-disable;
			drive-strength = <0x02>;
			phandle = <0x7a>;
		};

		pcfg-pull-none-drv-level-3 {
			bias-disable;
			drive-strength = <0x03>;
			phandle = <0x7e>;
		};

		pcfg-pull-none-drv-level-4 {
			bias-disable;
			drive-strength = <0x04>;
			phandle = <0xcf>;
		};

		pcfg-pull-none-drv-level-5 {
			bias-disable;
			drive-strength = <0x05>;
			phandle = <0xd0>;
		};

		pcfg-pull-none-drv-level-6 {
			bias-disable;
			drive-strength = <0x06>;
			phandle = <0xd1>;
		};

		pcfg-pull-none-drv-level-7 {
			bias-disable;
			drive-strength = <0x07>;
			phandle = <0xd2>;
		};

		pcfg-pull-none-drv-level-8 {
			bias-disable;
			drive-strength = <0x08>;
			phandle = <0xd3>;
		};

		pcfg-pull-none-drv-level-9 {
			bias-disable;
			drive-strength = <0x09>;
			phandle = <0xd4>;
		};

		pcfg-pull-none-drv-level-10 {
			bias-disable;
			drive-strength = <0x0a>;
			phandle = <0xd5>;
		};

		pcfg-pull-none-drv-level-11 {
			bias-disable;
			drive-strength = <0x0b>;
			phandle = <0xd6>;
		};

		pcfg-pull-none-drv-level-12 {
			bias-disable;
			drive-strength = <0x0c>;
			phandle = <0xd7>;
		};

		pcfg-pull-none-drv-level-13 {
			bias-disable;
			drive-strength = <0x0d>;
			phandle = <0xd8>;
		};

		pcfg-pull-none-drv-level-14 {
			bias-disable;
			drive-strength = <0x0e>;
			phandle = <0xd9>;
		};

		pcfg-pull-none-drv-level-15 {
			bias-disable;
			drive-strength = <0x0f>;
			phandle = <0xda>;
		};

		pcfg-pull-up-drv-level-0 {
			bias-pull-up;
			drive-strength = <0x00>;
			phandle = <0xdb>;
		};

		pcfg-pull-up-drv-level-1 {
			bias-pull-up;
			drive-strength = <0x01>;
			phandle = <0x7d>;
		};

		pcfg-pull-up-drv-level-2 {
			bias-pull-up;
			drive-strength = <0x02>;
			phandle = <0x78>;
		};

		pcfg-pull-up-drv-level-3 {
			bias-pull-up;
			drive-strength = <0x03>;
			phandle = <0xdc>;
		};

		pcfg-pull-up-drv-level-4 {
			bias-pull-up;
			drive-strength = <0x04>;
			phandle = <0xdd>;
		};

		pcfg-pull-up-drv-level-5 {
			bias-pull-up;
			drive-strength = <0x05>;
			phandle = <0xde>;
		};

		pcfg-pull-up-drv-level-6 {
			bias-pull-up;
			drive-strength = <0x06>;
			phandle = <0xdf>;
		};

		pcfg-pull-up-drv-level-7 {
			bias-pull-up;
			drive-strength = <0x07>;
			phandle = <0xe0>;
		};

		pcfg-pull-up-drv-level-8 {
			bias-pull-up;
			drive-strength = <0x08>;
			phandle = <0xe1>;
		};

		pcfg-pull-up-drv-level-9 {
			bias-pull-up;
			drive-strength = <0x09>;
			phandle = <0xe2>;
		};

		pcfg-pull-up-drv-level-10 {
			bias-pull-up;
			drive-strength = <0x0a>;
			phandle = <0xe3>;
		};

		pcfg-pull-up-drv-level-11 {
			bias-pull-up;
			drive-strength = <0x0b>;
			phandle = <0xe4>;
		};

		pcfg-pull-up-drv-level-12 {
			bias-pull-up;
			drive-strength = <0x0c>;
			phandle = <0xe5>;
		};

		pcfg-pull-up-drv-level-13 {
			bias-pull-up;
			drive-strength = <0x0d>;
			phandle = <0xe6>;
		};

		pcfg-pull-up-drv-level-14 {
			bias-pull-up;
			drive-strength = <0x0e>;
			phandle = <0xe7>;
		};

		pcfg-pull-up-drv-level-15 {
			bias-pull-up;
			drive-strength = <0x0f>;
			phandle = <0xe8>;
		};

		pcfg-pull-down-drv-level-0 {
			bias-pull-down;
			drive-strength = <0x00>;
			phandle = <0xe9>;
		};

		pcfg-pull-down-drv-level-1 {
			bias-pull-down;
			drive-strength = <0x01>;
			phandle = <0xea>;
		};

		pcfg-pull-down-drv-level-2 {
			bias-pull-down;
			drive-strength = <0x02>;
			phandle = <0xeb>;
		};

		pcfg-pull-down-drv-level-3 {
			bias-pull-down;
			drive-strength = <0x03>;
			phandle = <0xec>;
		};

		pcfg-pull-down-drv-level-4 {
			bias-pull-down;
			drive-strength = <0x04>;
			phandle = <0xed>;
		};

		pcfg-pull-down-drv-level-5 {
			bias-pull-down;
			drive-strength = <0x05>;
			phandle = <0xee>;
		};

		pcfg-pull-down-drv-level-6 {
			bias-pull-down;
			drive-strength = <0x06>;
			phandle = <0xef>;
		};

		pcfg-pull-down-drv-level-7 {
			bias-pull-down;
			drive-strength = <0x07>;
			phandle = <0xf0>;
		};

		pcfg-pull-down-drv-level-8 {
			bias-pull-down;
			drive-strength = <0x08>;
			phandle = <0xf1>;
		};

		pcfg-pull-down-drv-level-9 {
			bias-pull-down;
			drive-strength = <0x09>;
			phandle = <0xf2>;
		};

		pcfg-pull-down-drv-level-10 {
			bias-pull-down;
			drive-strength = <0x0a>;
			phandle = <0xf3>;
		};

		pcfg-pull-down-drv-level-11 {
			bias-pull-down;
			drive-strength = <0x0b>;
			phandle = <0xf4>;
		};

		pcfg-pull-down-drv-level-12 {
			bias-pull-down;
			drive-strength = <0x0c>;
			phandle = <0xf5>;
		};

		pcfg-pull-down-drv-level-13 {
			bias-pull-down;
			drive-strength = <0x0d>;
			phandle = <0xf6>;
		};

		pcfg-pull-down-drv-level-14 {
			bias-pull-down;
			drive-strength = <0x0e>;
			phandle = <0xf7>;
		};

		pcfg-pull-down-drv-level-15 {
			bias-pull-down;
			drive-strength = <0x0f>;
			phandle = <0xf8>;
		};

		pcfg-pull-up-smt {
			bias-pull-up;
			input-schmitt-enable;
			phandle = <0xf9>;
		};

		pcfg-pull-down-smt {
			bias-pull-down;
			input-schmitt-enable;
			phandle = <0xfa>;
		};

		pcfg-pull-none-smt {
			bias-disable;
			input-schmitt-enable;
			phandle = <0x7c>;
		};

		pcfg-pull-none-drv-level-0-smt {
			bias-disable;
			drive-strength = <0x00>;
			input-schmitt-enable;
			phandle = <0xfb>;
		};

		pcfg-output-high {
			output-high;
			phandle = <0xfc>;
		};

		pcfg-output-low {
			output-low;
			phandle = <0xfd>;
		};

		acodec {

			acodec-pins {
				rockchip,pins = <0x01 0x09 0x05 0x77 0x01 0x01 0x05 0x77 0x01 0x00 0x05 0x77 0x01 0x07 0x05 0x77 0x01 0x08 0x05 0x77 0x01 0x03 0x05 0x77 0x01 0x05 0x05 0x77>;
				phandle = <0xfe>;
			};
		};

		audiopwm {

			audiopwm-lout {
				rockchip,pins = <0x01 0x00 0x04 0x77>;
				phandle = <0xff>;
			};

			audiopwm-loutn {
				rockchip,pins = <0x01 0x01 0x06 0x77>;
				phandle = <0x100>;
			};

			audiopwm-loutp {
				rockchip,pins = <0x01 0x00 0x06 0x77>;
				phandle = <0x101>;
			};

			audiopwm-rout {
				rockchip,pins = <0x01 0x01 0x04 0x77>;
				phandle = <0x102>;
			};

			audiopwm-routn {
				rockchip,pins = <0x01 0x07 0x04 0x77>;
				phandle = <0x103>;
			};

			audiopwm-routp {
				rockchip,pins = <0x01 0x06 0x04 0x77>;
				phandle = <0x104>;
			};
		};

		bt656 {

			bt656m0-pins {
				rockchip,pins = <0x03 0x00 0x02 0x77 0x02 0x18 0x02 0x77 0x02 0x19 0x02 0x77 0x02 0x1a 0x02 0x77 0x02 0x1b 0x02 0x77 0x02 0x1c 0x02 0x77 0x02 0x1d 0x02 0x77 0x02 0x1e 0x02 0x77 0x02 0x1f 0x02 0x77>;
				phandle = <0x105>;
			};

			bt656m1-pins {
				rockchip,pins = <0x04 0x0c 0x05 0x77 0x03 0x16 0x05 0x77 0x03 0x17 0x05 0x77 0x03 0x18 0x05 0x77 0x03 0x19 0x05 0x77 0x03 0x1a 0x05 0x77 0x03 0x1b 0x05 0x77 0x03 0x1c 0x05 0x77 0x03 0x1d 0x05 0x77>;
				phandle = <0x106>;
			};
		};

		bt1120 {

			bt1120-pins {
				rockchip,pins = <0x03 0x06 0x02 0x77 0x03 0x01 0x02 0x77 0x03 0x02 0x02 0x77 0x03 0x03 0x02 0x77 0x03 0x04 0x02 0x77 0x03 0x05 0x02 0x77 0x03 0x07 0x02 0x77 0x03 0x08 0x02 0x77 0x03 0x09 0x02 0x77 0x03 0x0a 0x02 0x77 0x03 0x0b 0x02 0x77 0x03 0x0c 0x02 0x77 0x03 0x0d 0x02 0x77 0x03 0x0e 0x02 0x77 0x03 0x11 0x02 0x77 0x03 0x12 0x02 0x77 0x03 0x13 0x02 0x77>;
				phandle = <0x107>;
			};
		};

		cam {

			cam-clkout0 {
				rockchip,pins = <0x04 0x07 0x01 0x77>;
				phandle = <0x108>;
			};

			cam-clkout1 {
				rockchip,pins = <0x04 0x08 0x01 0x77>;
				phandle = <0x109>;
			};
		};

		can0 {

			can0m0-pins {
				rockchip,pins = <0x00 0x0c 0x02 0x77 0x00 0x0b 0x02 0x77>;
				phandle = <0x10a>;
			};

			can0m1-pins {
				rockchip,pins = <0x02 0x02 0x04 0x77 0x02 0x01 0x04 0x77>;
				phandle = <0x10b>;
			};
		};

		can1 {

			can1m0-pins {
				rockchip,pins = <0x01 0x00 0x03 0x77 0x01 0x01 0x03 0x77>;
				phandle = <0x10c>;
			};

			can1m1-pins {
				rockchip,pins = <0x04 0x12 0x03 0x77 0x04 0x13 0x03 0x77>;
				phandle = <0x10d>;
			};
		};

		can2 {

			can2m0-pins {
				rockchip,pins = <0x04 0x0c 0x03 0x77 0x04 0x0d 0x03 0x77>;
				phandle = <0x10e>;
			};

			can2m1-pins {
				rockchip,pins = <0x02 0x09 0x04 0x77 0x02 0x0a 0x04 0x77>;
				phandle = <0x10f>;
			};
		};

		cif {

			cif-clk {
				rockchip,pins = <0x04 0x10 0x01 0x77>;
				phandle = <0x110>;
			};

			cif-dvp-clk {
				rockchip,pins = <0x04 0x11 0x01 0x77 0x04 0x0e 0x01 0x77 0x04 0x0f 0x01 0x77>;
				phandle = <0x111>;
			};

			cif-dvp-bus16 {
				rockchip,pins = <0x03 0x1e 0x01 0x77 0x03 0x1f 0x01 0x77 0x04 0x00 0x01 0x77 0x04 0x01 0x01 0x77 0x04 0x02 0x01 0x77 0x04 0x03 0x01 0x77 0x04 0x04 0x01 0x77 0x04 0x05 0x01 0x77>;
				phandle = <0x112>;
			};

			cif-dvp-bus8 {
				rockchip,pins = <0x03 0x16 0x01 0x77 0x03 0x17 0x01 0x77 0x03 0x18 0x01 0x77 0x03 0x19 0x01 0x77 0x03 0x1a 0x01 0x77 0x03 0x1b 0x01 0x77 0x03 0x1c 0x01 0x77 0x03 0x1d 0x01 0x77>;
				phandle = <0x113>;
			};
		};

		clk32k {

			clk32k-in {
				rockchip,pins = <0x00 0x08 0x01 0x77>;
				phandle = <0x114>;
			};

			clk32k-out0 {
				rockchip,pins = <0x00 0x08 0x02 0x77>;
				phandle = <0x09>;
			};

			clk32k-out1 {
				rockchip,pins = <0x02 0x16 0x01 0x77>;
				phandle = <0x115>;
			};
		};

		cpu {

			cpu-pins {
				rockchip,pins = <0x00 0x0f 0x02 0x77>;
				phandle = <0x116>;
			};
		};

		ebc {

			ebc-extern {
				rockchip,pins = <0x04 0x07 0x02 0x77 0x04 0x08 0x02 0x77 0x04 0x09 0x02 0x77 0x04 0x0d 0x02 0x77 0x04 0x0a 0x02 0x77>;
				phandle = <0x117>;
			};

			ebc-pins {
				rockchip,pins = <0x04 0x10 0x02 0x77 0x04 0x0b 0x02 0x77 0x04 0x0c 0x02 0x77 0x04 0x06 0x02 0x77 0x04 0x11 0x02 0x77 0x03 0x16 0x02 0x77 0x03 0x17 0x02 0x77 0x03 0x18 0x02 0x77 0x03 0x19 0x02 0x77 0x03 0x1a 0x02 0x77 0x03 0x1b 0x02 0x77 0x03 0x1c 0x02 0x77 0x03 0x1d 0x02 0x77 0x03 0x1e 0x02 0x77 0x03 0x1f 0x02 0x77 0x04 0x00 0x02 0x77 0x04 0x01 0x02 0x77 0x04 0x02 0x02 0x77 0x04 0x03 0x02 0x77 0x04 0x04 0x02 0x77 0x04 0x05 0x02 0x77 0x04 0x0e 0x02 0x77 0x04 0x0f 0x02 0x77>;
				phandle = <0x118>;
			};
		};

		edpdp {

			edpdpm0-pins {
				rockchip,pins = <0x04 0x14 0x01 0x77>;
				phandle = <0x119>;
			};

			edpdpm1-pins {
				rockchip,pins = <0x00 0x12 0x02 0x77>;
				phandle = <0x11a>;
			};
		};

		emmc {

			emmc-rstnout {
				rockchip,pins = <0x01 0x17 0x01 0x77>;
				phandle = <0x11b>;
			};

			emmc-bus8 {
				rockchip,pins = <0x01 0x0c 0x01 0x78 0x01 0x0d 0x01 0x78 0x01 0x0e 0x01 0x78 0x01 0x0f 0x01 0x78 0x01 0x10 0x01 0x78 0x01 0x11 0x01 0x78 0x01 0x12 0x01 0x78 0x01 0x13 0x01 0x78>;
				phandle = <0x45>;
			};

			emmc-clk {
				rockchip,pins = <0x01 0x15 0x01 0x78>;
				phandle = <0x46>;
			};

			emmc-cmd {
				rockchip,pins = <0x01 0x14 0x01 0x78>;
				phandle = <0x47>;
			};

			emmc-datastrobe {
				rockchip,pins = <0x01 0x16 0x01 0x77>;
				phandle = <0x48>;
			};
		};

		eth0 {

			eth0-pins {
				rockchip,pins = <0x02 0x11 0x02 0x77>;
				phandle = <0x11c>;
			};
		};

		eth1 {

			eth1m0-pins {
				rockchip,pins = <0x03 0x08 0x03 0x77>;
				phandle = <0x11d>;
			};

			eth1m1-pins {
				rockchip,pins = <0x04 0x0b 0x03 0x77>;
				phandle = <0x11e>;
			};
		};

		flash {

			flash-pins {
				rockchip,pins = <0x01 0x18 0x02 0x77 0x01 0x16 0x03 0x77 0x01 0x1b 0x02 0x77 0x01 0x1c 0x02 0x77 0x01 0x0c 0x02 0x77 0x01 0x0d 0x02 0x77 0x01 0x0e 0x02 0x77 0x01 0x0f 0x02 0x77 0x01 0x10 0x02 0x77 0x01 0x11 0x02 0x77 0x01 0x12 0x02 0x77 0x01 0x13 0x02 0x77 0x01 0x15 0x02 0x77 0x01 0x1a 0x02 0x77 0x01 0x19 0x02 0x77 0x00 0x07 0x01 0x77 0x01 0x17 0x03 0x77 0x01 0x14 0x02 0x77>;
				phandle = <0x11f>;
			};
		};

		fspi {

			fspi-pins {
				rockchip,pins = <0x01 0x18 0x01 0x77 0x01 0x1b 0x01 0x77 0x01 0x19 0x01 0x77 0x01 0x1a 0x01 0x77 0x01 0x17 0x02 0x77 0x01 0x1c 0x01 0x77>;
				phandle = <0x120>;
			};

			fspi-cs1 {
				rockchip,pins = <0x01 0x16 0x02 0x79>;
				phandle = <0x121>;
			};
		};

		gmac0 {

			gmac0-miim {
				rockchip,pins = <0x02 0x13 0x02 0x77 0x02 0x14 0x02 0x77>;
				phandle = <0x83>;
			};

			gmac0-clkinout {
				rockchip,pins = <0x02 0x12 0x02 0x77>;
				phandle = <0x122>;
			};

			gmac0-rx-er {
				rockchip,pins = <0x02 0x15 0x02 0x77>;
				phandle = <0x123>;
			};

			gmac0-rx-bus2 {
				rockchip,pins = <0x02 0x0e 0x01 0x77 0x02 0x0f 0x02 0x77 0x02 0x10 0x02 0x77>;
				phandle = <0x85>;
			};

			gmac0-tx-bus2 {
				rockchip,pins = <0x02 0x0b 0x01 0x7a 0x02 0x0c 0x01 0x7a 0x02 0x0d 0x01 0x77>;
				phandle = <0x84>;
			};

			gmac0-rgmii-clk {
				rockchip,pins = <0x02 0x05 0x02 0x77 0x02 0x08 0x02 0x7b>;
				phandle = <0x86>;
			};

			gmac0-rgmii-bus {
				rockchip,pins = <0x02 0x03 0x02 0x77 0x02 0x04 0x02 0x77 0x02 0x06 0x02 0x7a 0x02 0x07 0x02 0x7a>;
				phandle = <0x87>;
			};
		};

		gmac1 {

			gmac1m0-miim {
				rockchip,pins = <0x03 0x14 0x03 0x77 0x03 0x15 0x03 0x77>;
				phandle = <0x124>;
			};

			gmac1m0-clkinout {
				rockchip,pins = <0x03 0x10 0x03 0x77>;
				phandle = <0x125>;
			};

			gmac1m0-rx-er {
				rockchip,pins = <0x03 0x0c 0x03 0x77>;
				phandle = <0x126>;
			};

			gmac1m0-rx-bus2 {
				rockchip,pins = <0x03 0x09 0x03 0x77 0x03 0x0a 0x03 0x77 0x03 0x0b 0x03 0x77>;
				phandle = <0x127>;
			};

			gmac1m0-tx-bus2 {
				rockchip,pins = <0x03 0x0d 0x03 0x7a 0x03 0x0e 0x03 0x7a 0x03 0x0f 0x03 0x77>;
				phandle = <0x128>;
			};

			gmac1m0-rgmii-clk {
				rockchip,pins = <0x03 0x07 0x03 0x77 0x03 0x06 0x03 0x7b>;
				phandle = <0x129>;
			};

			gmac1m0-rgmii-bus {
				rockchip,pins = <0x03 0x04 0x03 0x77 0x03 0x05 0x03 0x77 0x03 0x02 0x03 0x7a 0x03 0x03 0x03 0x7a>;
				phandle = <0x12a>;
			};

			gmac1m1-miim {
				rockchip,pins = <0x04 0x0e 0x03 0x77 0x04 0x0f 0x03 0x77>;
				phandle = <0x3a>;
			};

			gmac1m1-clkinout {
				rockchip,pins = <0x04 0x11 0x03 0x77>;
				phandle = <0x12b>;
			};

			gmac1m1-rx-er {
				rockchip,pins = <0x04 0x0a 0x03 0x77>;
				phandle = <0x12c>;
			};

			gmac1m1-rx-bus2 {
				rockchip,pins = <0x04 0x07 0x03 0x77 0x04 0x08 0x03 0x77 0x04 0x09 0x03 0x77>;
				phandle = <0x3c>;
			};

			gmac1m1-tx-bus2 {
				rockchip,pins = <0x04 0x04 0x03 0x7a 0x04 0x05 0x03 0x7a 0x04 0x06 0x03 0x77>;
				phandle = <0x3b>;
			};

			gmac1m1-rgmii-clk {
				rockchip,pins = <0x04 0x03 0x03 0x77 0x04 0x00 0x03 0x7b>;
				phandle = <0x3d>;
			};

			gmac1m1-rgmii-bus {
				rockchip,pins = <0x04 0x01 0x03 0x77 0x04 0x02 0x03 0x77 0x03 0x1e 0x03 0x7a 0x03 0x1f 0x03 0x7a>;
				phandle = <0x3e>;
			};
		};

		gpu {

			gpu-pins {
				rockchip,pins = <0x00 0x10 0x02 0x77 0x00 0x06 0x04 0x77>;
				phandle = <0x12d>;
			};
		};

		hdmitx {

			hdmitxm0-cec {
				rockchip,pins = <0x04 0x19 0x01 0x77>;
				phandle = <0x12e>;
			};

			hdmitxm1-cec {
				rockchip,pins = <0x00 0x17 0x01 0x77>;
				phandle = <0x12f>;
			};

			hdmitx-scl {
				rockchip,pins = <0x04 0x17 0x01 0x77>;
				phandle = <0x130>;
			};

			hdmitx-sda {
				rockchip,pins = <0x04 0x18 0x01 0x77>;
				phandle = <0x131>;
			};
		};

		i2c0 {

			i2c0-xfer {
				rockchip,pins = <0x00 0x09 0x01 0x7c 0x00 0x0a 0x01 0x7c>;
				phandle = <0x12>;
			};
		};

		i2c1 {

			i2c1-xfer {
				rockchip,pins = <0x00 0x0b 0x01 0x7c 0x00 0x0c 0x01 0x7c>;
				phandle = <0x57>;
			};
		};

		i2c2 {

			i2c2m0-xfer {
				rockchip,pins = <0x00 0x0d 0x01 0x7c 0x00 0x0e 0x01 0x7c>;
				phandle = <0x58>;
			};

			i2c2m1-xfer {
				rockchip,pins = <0x04 0x0d 0x01 0x7c 0x04 0x0c 0x01 0x7c>;
				phandle = <0x132>;
			};
		};

		i2c3 {

			i2c3m0-xfer {
				rockchip,pins = <0x01 0x01 0x01 0x7c 0x01 0x00 0x01 0x7c>;
				phandle = <0x59>;
			};

			i2c3m1-xfer {
				rockchip,pins = <0x03 0x0d 0x04 0x7c 0x03 0x0e 0x04 0x7c>;
				phandle = <0x133>;
			};
		};

		i2c4 {

			i2c4m0-xfer {
				rockchip,pins = <0x04 0x0b 0x01 0x7c 0x04 0x0a 0x01 0x7c>;
				phandle = <0x5a>;
			};

			i2c4m1-xfer {
				rockchip,pins = <0x02 0x0a 0x02 0x7c 0x02 0x09 0x02 0x7c>;
				phandle = <0x134>;
			};
		};

		i2c5 {

			i2c5m0-xfer {
				rockchip,pins = <0x03 0x0b 0x04 0x7c 0x03 0x0c 0x04 0x7c>;
				phandle = <0x5b>;
			};

			i2c5m1-xfer {
				rockchip,pins = <0x04 0x17 0x02 0x7c 0x04 0x18 0x02 0x7c>;
				phandle = <0x135>;
			};
		};

		i2s1 {

			i2s1m0-lrckrx {
				rockchip,pins = <0x01 0x06 0x01 0x77>;
				phandle = <0x4e>;
			};

			i2s1m0-lrcktx {
				rockchip,pins = <0x01 0x05 0x01 0x77>;
				phandle = <0x4d>;
			};

			i2s1m0-mclk {
				rockchip,pins = <0x01 0x02 0x01 0x77>;
				phandle = <0x136>;
			};

			i2s1m0-sclkrx {
				rockchip,pins = <0x01 0x04 0x01 0x77>;
				phandle = <0x4c>;
			};

			i2s1m0-sclktx {
				rockchip,pins = <0x01 0x03 0x01 0x77>;
				phandle = <0x4b>;
			};

			i2s1m0-sdi0 {
				rockchip,pins = <0x01 0x0b 0x01 0x77>;
				phandle = <0x4f>;
			};

			i2s1m0-sdi1 {
				rockchip,pins = <0x01 0x0a 0x02 0x77>;
				phandle = <0x50>;
			};

			i2s1m0-sdi2 {
				rockchip,pins = <0x01 0x09 0x02 0x77>;
				phandle = <0x51>;
			};

			i2s1m0-sdi3 {
				rockchip,pins = <0x01 0x08 0x02 0x77>;
				phandle = <0x52>;
			};

			i2s1m0-sdo0 {
				rockchip,pins = <0x01 0x07 0x01 0x77>;
				phandle = <0x53>;
			};

			i2s1m0-sdo1 {
				rockchip,pins = <0x01 0x08 0x01 0x77>;
				phandle = <0x54>;
			};

			i2s1m0-sdo2 {
				rockchip,pins = <0x01 0x09 0x01 0x77>;
				phandle = <0x55>;
			};

			i2s1m0-sdo3 {
				rockchip,pins = <0x01 0x0a 0x01 0x77>;
				phandle = <0x56>;
			};

			i2s1m1-lrckrx {
				rockchip,pins = <0x04 0x07 0x05 0x77>;
				phandle = <0x137>;
			};

			i2s1m1-lrcktx {
				rockchip,pins = <0x03 0x18 0x04 0x77>;
				phandle = <0x138>;
			};

			i2s1m1-mclk {
				rockchip,pins = <0x03 0x16 0x04 0x77>;
				phandle = <0x139>;
			};

			i2s1m1-sclkrx {
				rockchip,pins = <0x04 0x06 0x05 0x77>;
				phandle = <0x13a>;
			};

			i2s1m1-sclktx {
				rockchip,pins = <0x03 0x17 0x04 0x77>;
				phandle = <0x13b>;
			};

			i2s1m1-sdi0 {
				rockchip,pins = <0x03 0x1a 0x04 0x77>;
				phandle = <0x13c>;
			};

			i2s1m1-sdi1 {
				rockchip,pins = <0x03 0x1b 0x04 0x77>;
				phandle = <0x13d>;
			};

			i2s1m1-sdi2 {
				rockchip,pins = <0x03 0x1c 0x04 0x77>;
				phandle = <0x13e>;
			};

			i2s1m1-sdi3 {
				rockchip,pins = <0x03 0x1d 0x04 0x77>;
				phandle = <0x13f>;
			};

			i2s1m1-sdo0 {
				rockchip,pins = <0x03 0x19 0x04 0x77>;
				phandle = <0x140>;
			};

			i2s1m1-sdo1 {
				rockchip,pins = <0x04 0x08 0x05 0x77>;
				phandle = <0x141>;
			};

			i2s1m1-sdo2 {
				rockchip,pins = <0x04 0x09 0x04 0x77>;
				phandle = <0x142>;
			};

			i2s1m1-sdo3 {
				rockchip,pins = <0x04 0x0d 0x04 0x77>;
				phandle = <0x143>;
			};

			i2s1m2-lrckrx {
				rockchip,pins = <0x03 0x15 0x05 0x77>;
				phandle = <0x144>;
			};

			i2s1m2-lrcktx {
				rockchip,pins = <0x02 0x1a 0x05 0x77>;
				phandle = <0x145>;
			};

			i2s1m2-mclk {
				rockchip,pins = <0x02 0x18 0x05 0x77>;
				phandle = <0x146>;
			};

			i2s1m2-sclkrx {
				rockchip,pins = <0x03 0x13 0x05 0x77>;
				phandle = <0x147>;
			};

			i2s1m2-sclktx {
				rockchip,pins = <0x02 0x19 0x05 0x77>;
				phandle = <0x148>;
			};

			i2s1m2-sdi0 {
				rockchip,pins = <0x02 0x1b 0x05 0x77>;
				phandle = <0x149>;
			};

			i2s1m2-sdi1 {
				rockchip,pins = <0x02 0x1c 0x05 0x77>;
				phandle = <0x14a>;
			};

			i2s1m2-sdi2 {
				rockchip,pins = <0x02 0x1d 0x05 0x77>;
				phandle = <0x14b>;
			};

			i2s1m2-sdi3 {
				rockchip,pins = <0x02 0x1e 0x05 0x77>;
				phandle = <0x14c>;
			};

			i2s1m2-sdo0 {
				rockchip,pins = <0x02 0x1f 0x05 0x77>;
				phandle = <0x14d>;
			};

			i2s1m2-sdo1 {
				rockchip,pins = <0x03 0x00 0x05 0x77>;
				phandle = <0x14e>;
			};

			i2s1m2-sdo2 {
				rockchip,pins = <0x03 0x11 0x05 0x77>;
				phandle = <0x14f>;
			};

			i2s1m2-sdo3 {
				rockchip,pins = <0x03 0x12 0x05 0x77>;
				phandle = <0x150>;
			};
		};

		i2s2 {

			i2s2m0-lrckrx {
				rockchip,pins = <0x02 0x10 0x01 0x77>;
				phandle = <0x151>;
			};

			i2s2m0-lrcktx {
				rockchip,pins = <0x02 0x13 0x01 0x77>;
				phandle = <0x152>;
			};

			i2s2m0-mclk {
				rockchip,pins = <0x02 0x11 0x01 0x77>;
				phandle = <0x153>;
			};

			i2s2m0-sclkrx {
				rockchip,pins = <0x02 0x0f 0x01 0x77>;
				phandle = <0x154>;
			};

			i2s2m0-sclktx {
				rockchip,pins = <0x02 0x12 0x01 0x77>;
				phandle = <0x155>;
			};

			i2s2m0-sdi {
				rockchip,pins = <0x02 0x15 0x01 0x77>;
				phandle = <0x156>;
			};

			i2s2m0-sdo {
				rockchip,pins = <0x02 0x14 0x01 0x77>;
				phandle = <0x157>;
			};

			i2s2m1-lrckrx {
				rockchip,pins = <0x04 0x05 0x05 0x77>;
				phandle = <0x158>;
			};

			i2s2m1-lrcktx {
				rockchip,pins = <0x04 0x04 0x05 0x77>;
				phandle = <0x159>;
			};

			i2s2m1-mclk {
				rockchip,pins = <0x04 0x0e 0x05 0x77>;
				phandle = <0x15a>;
			};

			i2s2m1-sclkrx {
				rockchip,pins = <0x04 0x11 0x05 0x77>;
				phandle = <0x15b>;
			};

			i2s2m1-sclktx {
				rockchip,pins = <0x04 0x0f 0x04 0x77>;
				phandle = <0x15c>;
			};

			i2s2m1-sdi {
				rockchip,pins = <0x04 0x0a 0x05 0x77>;
				phandle = <0x15d>;
			};

			i2s2m1-sdo {
				rockchip,pins = <0x04 0x0b 0x05 0x77>;
				phandle = <0x15e>;
			};
		};

		i2s3 {

			i2s3m0-lrck {
				rockchip,pins = <0x03 0x04 0x04 0x77>;
				phandle = <0x15f>;
			};

			i2s3m0-mclk {
				rockchip,pins = <0x03 0x02 0x04 0x77>;
				phandle = <0x160>;
			};

			i2s3m0-sclk {
				rockchip,pins = <0x03 0x03 0x04 0x77>;
				phandle = <0x161>;
			};

			i2s3m0-sdi {
				rockchip,pins = <0x03 0x06 0x04 0x77>;
				phandle = <0x162>;
			};

			i2s3m0-sdo {
				rockchip,pins = <0x03 0x05 0x04 0x77>;
				phandle = <0x163>;
			};

			i2s3m1-lrck {
				rockchip,pins = <0x04 0x14 0x05 0x77>;
				phandle = <0x164>;
			};

			i2s3m1-mclk {
				rockchip,pins = <0x04 0x12 0x05 0x77>;
				phandle = <0x165>;
			};

			i2s3m1-sclk {
				rockchip,pins = <0x04 0x13 0x05 0x77>;
				phandle = <0x166>;
			};

			i2s3m1-sdi {
				rockchip,pins = <0x04 0x16 0x05 0x77>;
				phandle = <0x167>;
			};

			i2s3m1-sdo {
				rockchip,pins = <0x04 0x15 0x05 0x77>;
				phandle = <0x168>;
			};
		};

		isp {

			isp-pins {
				rockchip,pins = <0x04 0x0c 0x04 0x77 0x04 0x06 0x01 0x77 0x04 0x09 0x01 0x77>;
				phandle = <0x169>;
			};
		};

		jtag {

			jtag-pins {
				rockchip,pins = <0x01 0x1f 0x02 0x77 0x02 0x00 0x02 0x77>;
				phandle = <0x16a>;
			};
		};

		lcdc {

			lcdc-ctl {
				rockchip,pins = <0x03 0x00 0x01 0x77 0x02 0x18 0x01 0x77 0x02 0x19 0x01 0x77 0x02 0x1a 0x01 0x77 0x02 0x1b 0x01 0x77 0x02 0x1c 0x01 0x77 0x02 0x1d 0x01 0x77 0x02 0x1e 0x01 0x77 0x02 0x1f 0x01 0x77 0x03 0x01 0x01 0x77 0x03 0x02 0x01 0x77 0x03 0x03 0x01 0x77 0x03 0x04 0x01 0x77 0x03 0x05 0x01 0x77 0x03 0x06 0x01 0x77 0x03 0x07 0x01 0x77 0x03 0x08 0x01 0x77 0x03 0x09 0x01 0x77 0x03 0x0a 0x01 0x77 0x03 0x0b 0x01 0x77 0x03 0x0c 0x01 0x77 0x03 0x0d 0x01 0x77 0x03 0x0e 0x01 0x77 0x03 0x0f 0x01 0x77 0x03 0x10 0x01 0x77 0x03 0x13 0x01 0x77 0x03 0x11 0x01 0x77 0x03 0x12 0x01 0x77>;
				phandle = <0x16b>;
			};
		};

		mcu {

			mcu-pins {
				rockchip,pins = <0x00 0x0c 0x04 0x77 0x00 0x11 0x04 0x77 0x00 0x0b 0x04 0x77 0x00 0x12 0x04 0x77 0x00 0x13 0x04 0x77>;
				phandle = <0x16c>;
			};
		};

		npu {

			npu-pins {
				rockchip,pins = <0x00 0x11 0x02 0x77>;
				phandle = <0x16d>;
			};
		};

		pcie20 {

			pcie20m0-pins {
				rockchip,pins = <0x00 0x05 0x03 0x77 0x00 0x0e 0x03 0x77 0x00 0x0d 0x03 0x77>;
				phandle = <0x16e>;
			};

			pcie20m1-pins {
				rockchip,pins = <0x02 0x18 0x04 0x77 0x03 0x11 0x04 0x77 0x02 0x19 0x04 0x77>;
				phandle = <0x16f>;
			};

			pcie20m2-pins {
				rockchip,pins = <0x01 0x08 0x04 0x77 0x01 0x0a 0x04 0x77 0x01 0x09 0x04 0x77>;
				phandle = <0x170>;
			};

			pcie20-buttonrstn {
				rockchip,pins = <0x00 0x0c 0x03 0x77>;
				phandle = <0x171>;
			};
		};

		pcie30x1 {

			pcie30x1m0-pins {
				rockchip,pins = <0x00 0x04 0x03 0x77 0x00 0x13 0x03 0x77 0x00 0x12 0x03 0x77>;
				phandle = <0x172>;
			};

			pcie30x1m1-pins {
				rockchip,pins = <0x02 0x1a 0x04 0x77 0x03 0x01 0x04 0x77 0x02 0x1b 0x04 0x77>;
				phandle = <0x173>;
			};

			pcie30x1m2-pins {
				rockchip,pins = <0x01 0x05 0x04 0x77 0x01 0x02 0x04 0x77 0x01 0x03 0x04 0x77>;
				phandle = <0x174>;
			};

			pcie30x1-buttonrstn {
				rockchip,pins = <0x00 0x0b 0x03 0x77>;
				phandle = <0x175>;
			};
		};

		pcie30x2 {

			pcie30x2m0-pins {
				rockchip,pins = <0x00 0x06 0x02 0x77 0x00 0x16 0x03 0x77 0x00 0x15 0x03 0x77>;
				phandle = <0x176>;
			};

			pcie30x2m1-pins {
				rockchip,pins = <0x02 0x1c 0x04 0x77 0x02 0x1e 0x04 0x77 0x02 0x1d 0x04 0x77>;
				phandle = <0x177>;
			};

			pcie30x2m2-pins {
				rockchip,pins = <0x04 0x12 0x04 0x77 0x04 0x14 0x04 0x77 0x04 0x13 0x04 0x77>;
				phandle = <0x178>;
			};

			pcie30x2-buttonrstn {
				rockchip,pins = <0x00 0x08 0x03 0x77>;
				phandle = <0x179>;
			};
		};

		pdm {

			pdmm0-clk {
				rockchip,pins = <0x01 0x06 0x03 0x77>;
				phandle = <0x17a>;
			};

			pdmm0-clk1 {
				rockchip,pins = <0x01 0x04 0x03 0x77>;
				phandle = <0x17b>;
			};

			pdmm0-sdi0 {
				rockchip,pins = <0x01 0x0b 0x02 0x77>;
				phandle = <0x17c>;
			};

			pdmm0-sdi1 {
				rockchip,pins = <0x01 0x0a 0x03 0x77>;
				phandle = <0x17d>;
			};

			pdmm0-sdi2 {
				rockchip,pins = <0x01 0x09 0x03 0x77>;
				phandle = <0x17e>;
			};

			pdmm0-sdi3 {
				rockchip,pins = <0x01 0x08 0x03 0x77>;
				phandle = <0x17f>;
			};

			pdmm1-clk {
				rockchip,pins = <0x03 0x1e 0x05 0x77>;
				phandle = <0x180>;
			};

			pdmm1-clk1 {
				rockchip,pins = <0x04 0x00 0x04 0x77>;
				phandle = <0x181>;
			};

			pdmm1-sdi0 {
				rockchip,pins = <0x03 0x1f 0x05 0x77>;
				phandle = <0x182>;
			};

			pdmm1-sdi1 {
				rockchip,pins = <0x04 0x01 0x04 0x77>;
				phandle = <0x183>;
			};

			pdmm1-sdi2 {
				rockchip,pins = <0x04 0x02 0x05 0x77>;
				phandle = <0x184>;
			};

			pdmm1-sdi3 {
				rockchip,pins = <0x04 0x03 0x05 0x77>;
				phandle = <0x185>;
			};

			pdmm2-clk1 {
				rockchip,pins = <0x03 0x14 0x05 0x77>;
				phandle = <0x186>;
			};

			pdmm2-sdi0 {
				rockchip,pins = <0x03 0x0b 0x05 0x77>;
				phandle = <0x187>;
			};

			pdmm2-sdi1 {
				rockchip,pins = <0x03 0x0c 0x05 0x77>;
				phandle = <0x188>;
			};

			pdmm2-sdi2 {
				rockchip,pins = <0x03 0x0f 0x05 0x77>;
				phandle = <0x189>;
			};

			pdmm2-sdi3 {
				rockchip,pins = <0x03 0x10 0x05 0x77>;
				phandle = <0x18a>;
			};
		};

		pmic {

			pmic-pins {
				rockchip,pins = <0x00 0x02 0x01 0x77>;
				phandle = <0x18b>;
			};

			pmic_int {
				rockchip,pins = <0x00 0x03 0x00 0x79>;
				phandle = <0x14>;
			};
		};

		pmu {

			pmu-pins {
				rockchip,pins = <0x00 0x05 0x04 0x77 0x00 0x06 0x03 0x77 0x00 0x14 0x04 0x77 0x00 0x15 0x04 0x77 0x00 0x16 0x04 0x77 0x00 0x17 0x04 0x77>;
				phandle = <0x18c>;
			};
		};

		pwm0 {

			pwm0m0-pins {
				rockchip,pins = <0x00 0x0f 0x01 0x77>;
				phandle = <0x18>;
			};

			pwm0m1-pins {
				rockchip,pins = <0x00 0x17 0x02 0x77>;
				phandle = <0x18d>;
			};
		};

		pwm1 {

			pwm1m0-pins {
				rockchip,pins = <0x00 0x10 0x01 0x77>;
				phandle = <0x19>;
			};

			pwm1m1-pins {
				rockchip,pins = <0x00 0x0d 0x04 0x77>;
				phandle = <0x18e>;
			};
		};

		pwm2 {

			pwm2m0-pins {
				rockchip,pins = <0x00 0x11 0x01 0x77>;
				phandle = <0x1a>;
			};

			pwm2m1-pins {
				rockchip,pins = <0x00 0x0e 0x04 0x77>;
				phandle = <0x18f>;
			};
		};

		pwm3 {

			pwm3-pins {
				rockchip,pins = <0x00 0x12 0x01 0x77>;
				phandle = <0x1b>;
			};
		};

		pwm4 {

			pwm4-pins {
				rockchip,pins = <0x00 0x13 0x01 0x77>;
				phandle = <0x6a>;
			};
		};

		pwm5 {

			pwm5-pins {
				rockchip,pins = <0x00 0x14 0x01 0x77>;
				phandle = <0x6b>;
			};
		};

		pwm6 {

			pwm6-pins {
				rockchip,pins = <0x00 0x15 0x01 0x77>;
				phandle = <0x6c>;
			};
		};

		pwm7 {

			pwm7-pins {
				rockchip,pins = <0x00 0x16 0x01 0x77>;
				phandle = <0x6d>;
			};
		};

		pwm8 {

			pwm8m0-pins {
				rockchip,pins = <0x03 0x09 0x05 0x77>;
				phandle = <0x6e>;
			};

			pwm8m1-pins {
				rockchip,pins = <0x01 0x1d 0x04 0x77>;
				phandle = <0x190>;
			};
		};

		pwm9 {

			pwm9m0-pins {
				rockchip,pins = <0x03 0x0a 0x05 0x77>;
				phandle = <0x6f>;
			};

			pwm9m1-pins {
				rockchip,pins = <0x01 0x1e 0x04 0x77>;
				phandle = <0x191>;
			};
		};

		pwm10 {

			pwm10m0-pins {
				rockchip,pins = <0x03 0x0d 0x05 0x77>;
				phandle = <0x70>;
			};

			pwm10m1-pins {
				rockchip,pins = <0x02 0x01 0x02 0x77>;
				phandle = <0x192>;
			};
		};

		pwm11 {

			pwm11m0-pins {
				rockchip,pins = <0x03 0x0e 0x05 0x77>;
				phandle = <0x71>;
			};

			pwm11m1-pins {
				rockchip,pins = <0x04 0x10 0x03 0x77>;
				phandle = <0x193>;
			};
		};

		pwm12 {

			pwm12m0-pins {
				rockchip,pins = <0x03 0x0f 0x02 0x77>;
				phandle = <0x72>;
			};

			pwm12m1-pins {
				rockchip,pins = <0x04 0x15 0x01 0x77>;
				phandle = <0x194>;
			};
		};

		pwm13 {

			pwm13m0-pins {
				rockchip,pins = <0x03 0x10 0x02 0x77>;
				phandle = <0x73>;
			};

			pwm13m1-pins {
				rockchip,pins = <0x04 0x16 0x01 0x77>;
				phandle = <0x195>;
			};
		};

		pwm14 {

			pwm14m0-pins {
				rockchip,pins = <0x03 0x14 0x01 0x77>;
				phandle = <0x74>;
			};

			pwm14m1-pins {
				rockchip,pins = <0x04 0x12 0x01 0x77>;
				phandle = <0x196>;
			};
		};

		pwm15 {

			pwm15m0-pins {
				rockchip,pins = <0x03 0x15 0x01 0x77>;
				phandle = <0x75>;
			};

			pwm15m1-pins {
				rockchip,pins = <0x04 0x13 0x01 0x77>;
				phandle = <0x197>;
			};
		};

		refclk {

			refclk-pins {
				rockchip,pins = <0x00 0x00 0x01 0x77>;
				phandle = <0x198>;
			};
		};

		sata {

			sata-pins {
				rockchip,pins = <0x00 0x04 0x02 0x77 0x00 0x06 0x01 0x77 0x00 0x05 0x02 0x77>;
				phandle = <0x199>;
			};
		};

		sata0 {

			sata0-pins {
				rockchip,pins = <0x04 0x16 0x03 0x77>;
				phandle = <0x19a>;
			};
		};

		sata1 {

			sata1-pins {
				rockchip,pins = <0x04 0x15 0x03 0x77>;
				phandle = <0x19b>;
			};
		};

		sata2 {

			sata2-pins {
				rockchip,pins = <0x04 0x14 0x03 0x77>;
				phandle = <0x19c>;
			};
		};

		scr {

			scr-pins {
				rockchip,pins = <0x01 0x02 0x03 0x77 0x01 0x07 0x03 0x79 0x01 0x03 0x03 0x79 0x01 0x05 0x03 0x77>;
				phandle = <0x19d>;
			};
		};

		sdmmc0 {

			sdmmc0-bus4 {
				rockchip,pins = <0x01 0x1d 0x01 0x78 0x01 0x1e 0x01 0x78 0x01 0x1f 0x01 0x78 0x02 0x00 0x01 0x78>;
				phandle = <0x40>;
			};

			sdmmc0-clk {
				rockchip,pins = <0x02 0x02 0x01 0x78>;
				phandle = <0x41>;
			};

			sdmmc0-cmd {
				rockchip,pins = <0x02 0x01 0x01 0x78>;
				phandle = <0x42>;
			};

			sdmmc0-det {
				rockchip,pins = <0x00 0x04 0x01 0x79>;
				phandle = <0x43>;
			};

			sdmmc0-pwren {
				rockchip,pins = <0x00 0x05 0x01 0x77>;
				phandle = <0x19e>;
			};
		};

		sdmmc1 {

			sdmmc1-bus4 {
				rockchip,pins = <0x02 0x03 0x01 0x78 0x02 0x04 0x01 0x78 0x02 0x05 0x01 0x78 0x02 0x06 0x01 0x78>;
				phandle = <0x19f>;
			};

			sdmmc1-clk {
				rockchip,pins = <0x02 0x08 0x01 0x78>;
				phandle = <0x1a0>;
			};

			sdmmc1-cmd {
				rockchip,pins = <0x02 0x07 0x01 0x78>;
				phandle = <0x1a1>;
			};

			sdmmc1-det {
				rockchip,pins = <0x02 0x0a 0x01 0x79>;
				phandle = <0x1a2>;
			};

			sdmmc1-pwren {
				rockchip,pins = <0x02 0x09 0x01 0x77>;
				phandle = <0x1a3>;
			};
		};

		sdmmc2 {

			sdmmc2m0-bus4 {
				rockchip,pins = <0x03 0x16 0x03 0x78 0x03 0x17 0x03 0x78 0x03 0x18 0x03 0x78 0x03 0x19 0x03 0x78>;
				phandle = <0x1a4>;
			};

			sdmmc2m0-clk {
				rockchip,pins = <0x03 0x1b 0x03 0x78>;
				phandle = <0x1a5>;
			};

			sdmmc2m0-cmd {
				rockchip,pins = <0x03 0x1a 0x03 0x78>;
				phandle = <0x1a6>;
			};

			sdmmc2m0-det {
				rockchip,pins = <0x03 0x1c 0x03 0x79>;
				phandle = <0x1a7>;
			};

			sdmmc2m0-pwren {
				rockchip,pins = <0x03 0x1d 0x03 0x77>;
				phandle = <0x1a8>;
			};

			sdmmc2m1-bus4 {
				rockchip,pins = <0x03 0x01 0x05 0x78 0x03 0x02 0x05 0x78 0x03 0x03 0x05 0x78 0x03 0x04 0x05 0x78>;
				phandle = <0x1a9>;
			};

			sdmmc2m1-clk {
				rockchip,pins = <0x03 0x06 0x05 0x78>;
				phandle = <0x1aa>;
			};

			sdmmc2m1-cmd {
				rockchip,pins = <0x03 0x05 0x05 0x78>;
				phandle = <0x1ab>;
			};

			sdmmc2m1-det {
				rockchip,pins = <0x03 0x07 0x04 0x79>;
				phandle = <0x1ac>;
			};

			sdmmc2m1-pwren {
				rockchip,pins = <0x03 0x08 0x04 0x77>;
				phandle = <0x1ad>;
			};
		};

		spdif {

			spdifm0-tx {
				rockchip,pins = <0x01 0x04 0x04 0x77>;
				phandle = <0x4a>;
			};

			spdifm1-tx {
				rockchip,pins = <0x03 0x15 0x02 0x77>;
				phandle = <0x1ae>;
			};

			spdifm2-tx {
				rockchip,pins = <0x04 0x14 0x02 0x77>;
				phandle = <0x1af>;
			};
		};

		spi0 {

			spi0m0-pins {
				rockchip,pins = <0x00 0x0d 0x02 0x77 0x00 0x15 0x02 0x77 0x00 0x0e 0x02 0x77>;
				phandle = <0x1b0>;
			};

			spi0m0-cs0 {
				rockchip,pins = <0x00 0x16 0x02 0x77>;
				phandle = <0x1b1>;
			};

			spi0m0-cs1 {
				rockchip,pins = <0x00 0x14 0x02 0x77>;
				phandle = <0x1b2>;
			};

			spi0m1-pins {
				rockchip,pins = <0x02 0x1b 0x03 0x77 0x02 0x18 0x03 0x77 0x02 0x19 0x03 0x77>;
				phandle = <0x1b3>;
			};

			spi0m1-cs0 {
				rockchip,pins = <0x02 0x1a 0x03 0x77>;
				phandle = <0x1b4>;
			};
		};

		spi1 {

			spi1m0-pins {
				rockchip,pins = <0x02 0x0d 0x03 0x77 0x02 0x0e 0x03 0x77 0x02 0x0f 0x04 0x77>;
				phandle = <0x1b5>;
			};

			spi1m0-cs0 {
				rockchip,pins = <0x02 0x10 0x04 0x77>;
				phandle = <0x1b6>;
			};

			spi1m0-cs1 {
				rockchip,pins = <0x02 0x16 0x03 0x77>;
				phandle = <0x1b7>;
			};

			spi1m1-pins {
				rockchip,pins = <0x03 0x13 0x03 0x77 0x03 0x12 0x03 0x77 0x03 0x11 0x03 0x77>;
				phandle = <0x1b8>;
			};

			spi1m1-cs0 {
				rockchip,pins = <0x03 0x01 0x03 0x77>;
				phandle = <0x1b9>;
			};
		};

		spi2 {

			spi2m0-pins {
				rockchip,pins = <0x02 0x11 0x04 0x77 0x02 0x12 0x04 0x77 0x02 0x13 0x04 0x77>;
				phandle = <0x1ba>;
			};

			spi2m0-cs0 {
				rockchip,pins = <0x02 0x14 0x04 0x77>;
				phandle = <0x1bb>;
			};

			spi2m0-cs1 {
				rockchip,pins = <0x02 0x15 0x04 0x77>;
				phandle = <0x1bc>;
			};

			spi2m1-pins {
				rockchip,pins = <0x03 0x00 0x03 0x77 0x02 0x1f 0x03 0x77 0x02 0x1e 0x03 0x77>;
				phandle = <0x1bd>;
			};

			spi2m1-cs0 {
				rockchip,pins = <0x02 0x1d 0x03 0x77>;
				phandle = <0x1be>;
			};

			spi2m1-cs1 {
				rockchip,pins = <0x02 0x1c 0x03 0x77>;
				phandle = <0x1bf>;
			};
		};

		spi3 {

			spi3m0-pins {
				rockchip,pins = <0x04 0x0b 0x04 0x77 0x04 0x08 0x04 0x77 0x04 0x0a 0x04 0x77>;
				phandle = <0x1c0>;
			};

			spi3m0-cs0 {
				rockchip,pins = <0x04 0x06 0x04 0x77>;
				phandle = <0x1c1>;
			};

			spi3m0-cs1 {
				rockchip,pins = <0x04 0x07 0x04 0x77>;
				phandle = <0x1c2>;
			};

			spi3m1-pins {
				rockchip,pins = <0x04 0x12 0x02 0x77 0x04 0x15 0x02 0x77 0x04 0x13 0x02 0x77>;
				phandle = <0x1c3>;
			};

			spi3m1-cs0 {
				rockchip,pins = <0x04 0x16 0x02 0x77>;
				phandle = <0x1c4>;
			};

			spi3m1-cs1 {
				rockchip,pins = <0x04 0x19 0x02 0x77>;
				phandle = <0x1c5>;
			};
		};

		tsadc {

			tsadcm0-shut {
				rockchip,pins = <0x00 0x01 0x01 0x77>;
				phandle = <0x1c6>;
			};

			tsadcm1-shut {
				rockchip,pins = <0x00 0x02 0x02 0x77>;
				phandle = <0x1c7>;
			};

			tsadc-shutorg {
				rockchip,pins = <0x00 0x01 0x02 0x77>;
				phandle = <0x68>;
			};

			tsadc-pin {
				rockchip,pins = <0x00 0x01 0x00 0x77>;
				phandle = <0x67>;
			};
		};

		uart0 {

			uart0-xfer {
				rockchip,pins = <0x00 0x10 0x03 0x79 0x00 0x11 0x03 0x79>;
				phandle = <0x17>;
			};

			uart0-ctsn {
				rockchip,pins = <0x00 0x17 0x03 0x77>;
				phandle = <0x1c8>;
			};

			uart0-rtsn {
				rockchip,pins = <0x00 0x14 0x03 0x77>;
				phandle = <0x1c9>;
			};
		};

		uart1 {

			uart1m0-xfer {
				rockchip,pins = <0x02 0x0b 0x02 0x79 0x02 0x0c 0x02 0x79>;
				phandle = <0x5c>;
			};

			uart1m0-ctsn {
				rockchip,pins = <0x02 0x0e 0x02 0x77>;
				phandle = <0x1ca>;
			};

			uart1m0-rtsn {
				rockchip,pins = <0x02 0x0d 0x02 0x77>;
				phandle = <0x1cb>;
			};

			uart1m1-xfer {
				rockchip,pins = <0x03 0x1f 0x04 0x79 0x03 0x1e 0x04 0x79>;
				phandle = <0x1cc>;
			};

			uart1m1-ctsn {
				rockchip,pins = <0x04 0x11 0x04 0x77>;
				phandle = <0x1cd>;
			};

			uart1m1-rtsn {
				rockchip,pins = <0x04 0x0e 0x04 0x77>;
				phandle = <0x1ce>;
			};
		};

		uart2 {

			uart2m0-xfer {
				rockchip,pins = <0x00 0x18 0x01 0x79 0x00 0x19 0x01 0x79>;
				phandle = <0x5d>;
			};

			uart2m1-xfer {
				rockchip,pins = <0x01 0x1e 0x02 0x79 0x01 0x1d 0x02 0x79>;
				phandle = <0x1cf>;
			};
		};

		uart3 {

			uart3m0-xfer {
				rockchip,pins = <0x01 0x00 0x02 0x79 0x01 0x01 0x02 0x79>;
				phandle = <0x5e>;
			};

			uart3m0-ctsn {
				rockchip,pins = <0x01 0x03 0x02 0x77>;
				phandle = <0x1d0>;
			};

			uart3m0-rtsn {
				rockchip,pins = <0x01 0x02 0x02 0x77>;
				phandle = <0x1d1>;
			};

			uart3m1-xfer {
				rockchip,pins = <0x03 0x10 0x04 0x79 0x03 0x0f 0x04 0x79>;
				phandle = <0x1d2>;
			};
		};

		uart4 {

			uart4m0-xfer {
				rockchip,pins = <0x01 0x04 0x02 0x79 0x01 0x06 0x02 0x79>;
				phandle = <0x5f>;
			};

			uart4m0-ctsn {
				rockchip,pins = <0x01 0x07 0x02 0x77>;
				phandle = <0x1d3>;
			};

			uart4m0-rtsn {
				rockchip,pins = <0x01 0x05 0x02 0x77>;
				phandle = <0x1d4>;
			};

			uart4m1-xfer {
				rockchip,pins = <0x03 0x09 0x04 0x79 0x03 0x0a 0x04 0x79>;
				phandle = <0x1d5>;
			};
		};

		uart5 {

			uart5m0-xfer {
				rockchip,pins = <0x02 0x01 0x03 0x79 0x02 0x02 0x03 0x79>;
				phandle = <0x60>;
			};

			uart5m0-ctsn {
				rockchip,pins = <0x01 0x1f 0x03 0x77>;
				phandle = <0x1d6>;
			};

			uart5m0-rtsn {
				rockchip,pins = <0x02 0x00 0x03 0x77>;
				phandle = <0x1d7>;
			};

			uart5m1-xfer {
				rockchip,pins = <0x03 0x13 0x04 0x79 0x03 0x12 0x04 0x79>;
				phandle = <0x1d8>;
			};
		};

		uart6 {

			uart6m0-xfer {
				rockchip,pins = <0x02 0x03 0x03 0x79 0x02 0x04 0x03 0x79>;
				phandle = <0x61>;
			};

			uart6m0-ctsn {
				rockchip,pins = <0x02 0x10 0x03 0x77>;
				phandle = <0x1d9>;
			};

			uart6m0-rtsn {
				rockchip,pins = <0x02 0x0f 0x03 0x77>;
				phandle = <0x1da>;
			};

			uart6m1-xfer {
				rockchip,pins = <0x01 0x1e 0x03 0x79 0x01 0x1d 0x03 0x79>;
				phandle = <0x1db>;
			};
		};

		uart7 {

			uart7m0-xfer {
				rockchip,pins = <0x02 0x05 0x03 0x79 0x02 0x06 0x03 0x79>;
				phandle = <0x62>;
			};

			uart7m0-ctsn {
				rockchip,pins = <0x02 0x12 0x03 0x77>;
				phandle = <0x1dc>;
			};

			uart7m0-rtsn {
				rockchip,pins = <0x02 0x11 0x03 0x77>;
				phandle = <0x1dd>;
			};

			uart7m1-xfer {
				rockchip,pins = <0x03 0x15 0x04 0x79 0x03 0x14 0x04 0x79>;
				phandle = <0x1de>;
			};

			uart7m2-xfer {
				rockchip,pins = <0x04 0x03 0x04 0x79 0x04 0x02 0x04 0x79>;
				phandle = <0x1df>;
			};
		};

		uart8 {

			uart8m0-xfer {
				rockchip,pins = <0x02 0x16 0x02 0x79 0x02 0x15 0x03 0x79>;
				phandle = <0x63>;
			};

			uart8m0-ctsn {
				rockchip,pins = <0x02 0x0a 0x03 0x77>;
				phandle = <0x1e0>;
			};

			uart8m0-rtsn {
				rockchip,pins = <0x02 0x09 0x03 0x77>;
				phandle = <0x1e1>;
			};

			uart8m1-xfer {
				rockchip,pins = <0x03 0x00 0x04 0x79 0x02 0x1f 0x04 0x79>;
				phandle = <0x1e2>;
			};
		};

		uart9 {

			uart9m0-xfer {
				rockchip,pins = <0x02 0x07 0x03 0x79 0x02 0x08 0x03 0x79>;
				phandle = <0x64>;
			};

			uart9m0-ctsn {
				rockchip,pins = <0x02 0x14 0x03 0x77>;
				phandle = <0x1e3>;
			};

			uart9m0-rtsn {
				rockchip,pins = <0x02 0x13 0x03 0x77>;
				phandle = <0x1e4>;
			};

			uart9m1-xfer {
				rockchip,pins = <0x04 0x16 0x04 0x79 0x04 0x15 0x04 0x79>;
				phandle = <0x1e5>;
			};

			uart9m2-xfer {
				rockchip,pins = <0x04 0x05 0x04 0x79 0x04 0x04 0x04 0x79>;
				phandle = <0x1e6>;
			};
		};

		vop {

			vopm0-pins {
				rockchip,pins = <0x00 0x13 0x02 0x77>;
				phandle = <0x1e7>;
			};

			vopm1-pins {
				rockchip,pins = <0x03 0x14 0x02 0x77>;
				phandle = <0x1e8>;
			};
		};

		spi0-hs {

			spi0m0-pins {
				rockchip,pins = <0x00 0x0d 0x02 0x7d 0x00 0x15 0x02 0x7d 0x00 0x0e 0x02 0x7d>;
				phandle = <0x1e9>;
			};

			spi0m0-cs0 {
				rockchip,pins = <0x00 0x16 0x02 0x7d>;
				phandle = <0x1ea>;
			};

			spi0m0-cs1 {
				rockchip,pins = <0x00 0x14 0x02 0x7d>;
				phandle = <0x1eb>;
			};

			spi0m1-pins {
				rockchip,pins = <0x02 0x1b 0x03 0x7d 0x02 0x18 0x03 0x7d 0x02 0x19 0x03 0x7d>;
				phandle = <0x1ec>;
			};

			spi0m1-cs0 {
				rockchip,pins = <0x02 0x1a 0x03 0x7d>;
				phandle = <0x1ed>;
			};
		};

		spi1-hs {

			spi1m0-pins {
				rockchip,pins = <0x02 0x0d 0x03 0x7d 0x02 0x0e 0x03 0x7d 0x02 0x0f 0x04 0x7d>;
				phandle = <0x1ee>;
			};

			spi1m0-cs0 {
				rockchip,pins = <0x02 0x10 0x04 0x7d>;
				phandle = <0x1ef>;
			};

			spi1m0-cs1 {
				rockchip,pins = <0x02 0x16 0x03 0x7d>;
				phandle = <0x1f0>;
			};

			spi1m1-pins {
				rockchip,pins = <0x03 0x13 0x03 0x7d 0x03 0x12 0x03 0x7d 0x03 0x11 0x03 0x7d>;
				phandle = <0x1f1>;
			};

			spi1m1-cs0 {
				rockchip,pins = <0x03 0x01 0x03 0x7d>;
				phandle = <0x1f2>;
			};
		};

		spi2-hs {

			spi2m0-pins {
				rockchip,pins = <0x02 0x11 0x04 0x7d 0x02 0x12 0x04 0x7d 0x02 0x13 0x04 0x7d>;
				phandle = <0x1f3>;
			};

			spi2m0-cs0 {
				rockchip,pins = <0x02 0x14 0x04 0x7d>;
				phandle = <0x1f4>;
			};

			spi2m0-cs1 {
				rockchip,pins = <0x02 0x15 0x04 0x7d>;
				phandle = <0x1f5>;
			};

			spi2m1-pins {
				rockchip,pins = <0x03 0x00 0x03 0x7d 0x02 0x1f 0x03 0x7d 0x02 0x1e 0x03 0x7d>;
				phandle = <0x1f6>;
			};

			spi2m1-cs0 {
				rockchip,pins = <0x02 0x1d 0x03 0x7d>;
				phandle = <0x1f7>;
			};

			spi2m1-cs1 {
				rockchip,pins = <0x02 0x1c 0x03 0x7d>;
				phandle = <0x1f8>;
			};
		};

		spi3-hs {

			spi3m0-pins {
				rockchip,pins = <0x04 0x0b 0x04 0x7d 0x04 0x08 0x04 0x7d 0x04 0x0a 0x04 0x7d>;
				phandle = <0x1f9>;
			};

			spi3m0-cs0 {
				rockchip,pins = <0x04 0x06 0x04 0x7d>;
				phandle = <0x1fa>;
			};

			spi3m0-cs1 {
				rockchip,pins = <0x04 0x07 0x04 0x7d>;
				phandle = <0x1fb>;
			};

			spi3m1-pins {
				rockchip,pins = <0x04 0x12 0x02 0x7d 0x04 0x15 0x02 0x7d 0x04 0x13 0x02 0x7d>;
				phandle = <0x1fc>;
			};

			spi3m1-cs0 {
				rockchip,pins = <0x04 0x16 0x02 0x7d>;
				phandle = <0x1fd>;
			};

			spi3m1-cs1 {
				rockchip,pins = <0x04 0x19 0x02 0x7d>;
				phandle = <0x1fe>;
			};
		};

		gmac-txd-level3 {

			gmac0-tx-bus2-level3 {
				rockchip,pins = <0x02 0x0b 0x01 0x7e 0x02 0x0c 0x01 0x7e 0x02 0x0d 0x01 0x77>;
				phandle = <0x1ff>;
			};

			gmac0-rgmii-bus-level3 {
				rockchip,pins = <0x02 0x03 0x02 0x77 0x02 0x04 0x02 0x77 0x02 0x06 0x02 0x7e 0x02 0x07 0x02 0x7e>;
				phandle = <0x200>;
			};

			gmac1m0-tx-bus2-level3 {
				rockchip,pins = <0x03 0x0d 0x03 0x7e 0x03 0x0e 0x03 0x7e 0x03 0x0f 0x03 0x77>;
				phandle = <0x201>;
			};

			gmac1m0-rgmii-bus-level3 {
				rockchip,pins = <0x03 0x04 0x03 0x77 0x03 0x05 0x03 0x77 0x03 0x02 0x03 0x7e 0x03 0x03 0x03 0x7e>;
				phandle = <0x202>;
			};

			gmac1m1-tx-bus2-level3 {
				rockchip,pins = <0x04 0x04 0x03 0x7e 0x04 0x05 0x03 0x7e 0x04 0x06 0x03 0x77>;
				phandle = <0x203>;
			};

			gmac1m1-rgmii-bus-level3 {
				rockchip,pins = <0x04 0x01 0x03 0x77 0x04 0x02 0x03 0x77 0x03 0x1e 0x03 0x7e 0x03 0x1f 0x03 0x7e>;
				phandle = <0x204>;
			};
		};

		gmac-txc-level2 {

			gmac0-rgmii-clk-level2 {
				rockchip,pins = <0x02 0x05 0x02 0x77 0x02 0x08 0x02 0x7a>;
				phandle = <0x205>;
			};

			gmac1m0-rgmii-clk-level2 {
				rockchip,pins = <0x03 0x07 0x03 0x77 0x03 0x06 0x03 0x7a>;
				phandle = <0x206>;
			};

			gmac1m1-rgmii-clk-level2 {
				rockchip,pins = <0x04 0x03 0x03 0x77 0x04 0x00 0x03 0x7a>;
				phandle = <0x207>;
			};
		};
	};

	qos@fe190080 {
		compatible = "rockchip,rk3568-qos\0syscon";
		reg = <0x00 0xfe190080 0x00 0x20>;
		phandle = <0x2f>;
	};

	qos@fe190100 {
		compatible = "rockchip,rk3568-qos\0syscon";
		reg = <0x00 0xfe190100 0x00 0x20>;
		phandle = <0x30>;
	};

	qos@fe190200 {
		compatible = "rockchip,rk3568-qos\0syscon";
		reg = <0x00 0xfe190200 0x00 0x20>;
		phandle = <0x31>;
	};

	ethernet@fe2a0000 {
		compatible = "rockchip,rk3568-gmac\0snps,dwmac-4.20a";
		reg = <0x00 0xfe2a0000 0x00 0x10000>;
		interrupts = <0x00 0x1b 0x04 0x00 0x18 0x04>;
		interrupt-names = "macirq\0eth_wake_irq";
		clocks = <0x0f 0x182 0x0f 0x185 0x0f 0x185 0x0f 0xb8 0x0f 0xb4 0x0f 0xb5 0x0f 0x185 0x0f 0xb9>;
		clock-names = "stmmaceth\0mac_clk_rx\0mac_clk_tx\0clk_mac_refout\0aclk_mac\0pclk_mac\0clk_mac_speed\0ptp_ref";
		resets = <0x0f 0xd7>;
		reset-names = "stmmaceth";
		rockchip,grf = <0x11>;
		snps,axi-config = <0x7f>;
		snps,mixed-burst;
		snps,mtl-rx-config = <0x80>;
		snps,mtl-tx-config = <0x81>;
		snps,tso;
		status = "okay";
		assigned-clocks = <0x0f 0x185 0x0f 0x182>;
		assigned-clock-parents = <0x0f 0x183>;
		assigned-clock-rates = <0x00 0x7735940>;
		clock_in_out = "output";
		phy-handle = <0x82>;
		phy-mode = "rgmii-id";
		pinctrl-names = "default";
		pinctrl-0 = <0x83 0x84 0x85 0x86 0x87>;
		phandle = <0x208>;

		mdio {
			compatible = "snps,dwmac-mdio";
			#address-cells = <0x01>;
			#size-cells = <0x00>;
			phandle = <0x209>;

			ethernet-phy@0 {
				compatible = "ethernet-phy-ieee802.3-c22";
				reg = <0x00>;
				reset-assert-us = <0x4e20>;
				reset-deassert-us = <0x186a0>;
				reset-gpios = <0x3f 0x1b 0x01>;
				phandle = <0x82>;
			};
		};

		stmmac-axi-config {
			snps,blen = <0x00 0x00 0x00 0x00 0x10 0x08 0x04>;
			snps,rd_osr_lmt = <0x08>;
			snps,wr_osr_lmt = <0x04>;
			phandle = <0x7f>;
		};

		rx-queues-config {
			snps,rx-queues-to-use = <0x01>;
			phandle = <0x80>;

			queue0 {
			};
		};

		tx-queues-config {
			snps,tx-queues-to-use = <0x01>;
			phandle = <0x81>;

			queue0 {
			};
		};
	};

	chosen {
		stdout-path = "serial2:1500000n8";
		phandle = <0x20a>;
	};

	dc-12v {
		compatible = "regulator-fixed";
		regulator-name = "dc_12v";
		regulator-always-on;
		regulator-boot-on;
		regulator-min-microvolt = <0xb71b00>;
		regulator-max-microvolt = <0xb71b00>;
		phandle = <0x88>;
	};

	vcc3v3-sys {
		compatible = "regulator-fixed";
		regulator-name = "vcc3v3_sys";
		regulator-always-on;
		regulator-boot-on;
		regulator-min-microvolt = <0x325aa0>;
		regulator-max-microvolt = <0x325aa0>;
		vin-supply = <0x88>;
		phandle = <0x15>;
	};

	vcc5v0-sys {
		compatible = "regulator-fixed";
		regulator-name = "vcc5v0_sys";
		regulator-always-on;
		regulator-boot-on;
		regulator-min-microvolt = <0x4c4b40>;
		regulator-max-microvolt = <0x4c4b40>;
		vin-supply = <0x88>;
		phandle = <0x20b>;
	};

	vcc3v3-lcd0-n {
		compatible = "regulator-fixed";
		regulator-name = "vcc3v3_lcd0_n";
		regulator-boot-on;
		phandle = <0x20c>;

		regulator-state-mem {
			regulator-off-in-suspend;
		};
	};

	vcc3v3-lcd1-n {
		compatible = "regulator-fixed";
		regulator-name = "vcc3v3_lcd1_n";
		regulator-boot-on;
		phandle = <0x20d>;

		regulator-state-mem {
			regulator-off-in-suspend;
		};
	};

	__symbols__ {
		cpu0 = "/cpus/cpu@0";
		cpu1 = "/cpus/cpu@100";
		cpu2 = "/cpus/cpu@200";
		cpu3 = "/cpus/cpu@300";
		cpu0_opp_table = "/opp-table-0";
		scmi = "/firmware/scmi";
		scmi_clk = "/firmware/scmi/protocol@14";
		xin24m = "/xin24m";
		xin32k = "/xin32k";
		scmi_shmem = "/sram@10f000/sram@0";
		gic = "/interrupt-controller@fd400000";
		pmugrf = "/syscon@fdc20000";
		pmu_io_domains = "/syscon@fdc20000/io-domains";
		grf = "/syscon@fdc60000";
		pmucru = "/clock-controller@fdd00000";
		cru = "/clock-controller@fdd20000";
		i2c0 = "/i2c@fdd40000";
		rk809 = "/i2c@fdd40000/pmic@20";
		vdd_logic = "/i2c@fdd40000/pmic@20/regulators/DCDC_REG1";
		vdd_gpu = "/i2c@fdd40000/pmic@20/regulators/DCDC_REG2";
		vcc_ddr = "/i2c@fdd40000/pmic@20/regulators/DCDC_REG3";
		vdd_npu = "/i2c@fdd40000/pmic@20/regulators/DCDC_REG4";
		vcc_1v8 = "/i2c@fdd40000/pmic@20/regulators/DCDC_REG5";
		vdda0v9_image = "/i2c@fdd40000/pmic@20/regulators/LDO_REG1";
		vdda_0v9 = "/i2c@fdd40000/pmic@20/regulators/LDO_REG2";
		vdda0v9_pmu = "/i2c@fdd40000/pmic@20/regulators/LDO_REG3";
		vccio_acodec = "/i2c@fdd40000/pmic@20/regulators/LDO_REG4";
		vccio_sd = "/i2c@fdd40000/pmic@20/regulators/LDO_REG5";
		vcc3v3_pmu = "/i2c@fdd40000/pmic@20/regulators/LDO_REG6";
		vcca_1v8 = "/i2c@fdd40000/pmic@20/regulators/LDO_REG7";
		vcca1v8_pmu = "/i2c@fdd40000/pmic@20/regulators/LDO_REG8";
		vcca1v8_image = "/i2c@fdd40000/pmic@20/regulators/LDO_REG9";
		vcc_3v3 = "/i2c@fdd40000/pmic@20/regulators/SWITCH_REG1";
		vcc3v3_sd = "/i2c@fdd40000/pmic@20/regulators/SWITCH_REG2";
		uart0 = "/serial@fdd50000";
		pwm0 = "/pwm@fdd70000";
		pwm1 = "/pwm@fdd70010";
		pwm2 = "/pwm@fdd70020";
		pwm3 = "/pwm@fdd70030";
		pmu = "/power-management@fdd90000";
		power = "/power-management@fdd90000/power-controller";
		sdmmc2 = "/mmc@fe000000";
		gmac1 = "/ethernet@fe010000";
		mdio1 = "/ethernet@fe010000/mdio";
		rgmii_phy1 = "/ethernet@fe010000/mdio/ethernet-phy@0";
		gmac1_stmmac_axi_setup = "/ethernet@fe010000/stmmac-axi-config";
		gmac1_mtl_rx_setup = "/ethernet@fe010000/rx-queues-config";
		gmac1_mtl_tx_setup = "/ethernet@fe010000/tx-queues-config";
		qos_gpu = "/qos@fe128000";
		qos_rkvenc_rd_m0 = "/qos@fe138080";
		qos_rkvenc_rd_m1 = "/qos@fe138100";
		qos_rkvenc_wr_m0 = "/qos@fe138180";
		qos_isp = "/qos@fe148000";
		qos_vicap0 = "/qos@fe148080";
		qos_vicap1 = "/qos@fe148100";
		qos_vpu = "/qos@fe150000";
		qos_ebc = "/qos@fe158000";
		qos_iep = "/qos@fe158100";
		qos_jpeg_dec = "/qos@fe158180";
		qos_jpeg_enc = "/qos@fe158200";
		qos_rga_rd = "/qos@fe158280";
		qos_rga_wr = "/qos@fe158300";
		qos_npu = "/qos@fe180000";
		qos_pcie2x1 = "/qos@fe190000";
		qos_sata1 = "/qos@fe190280";
		qos_sata2 = "/qos@fe190300";
		qos_usb3_0 = "/qos@fe190380";
		qos_usb3_1 = "/qos@fe190400";
		qos_rkvdec = "/qos@fe198000";
		qos_hdcp = "/qos@fe1a8000";
		qos_vop_m0 = "/qos@fe1a8080";
		qos_vop_m1 = "/qos@fe1a8100";
		sdmmc0 = "/mmc@fe2b0000";
		sdmmc1 = "/mmc@fe2c0000";
		sdhci = "/mmc@fe310000";
		spdif = "/spdif@fe460000";
		i2s1_8ch = "/i2s@fe410000";
		dmac0 = "/dma-controller@fe530000";
		dmac1 = "/dma-controller@fe550000";
		i2c1 = "/i2c@fe5a0000";
		i2c2 = "/i2c@fe5b0000";
		i2c3 = "/i2c@fe5c0000";
		i2c4 = "/i2c@fe5d0000";
		i2c5 = "/i2c@fe5e0000";
		wdt = "/watchdog@fe600000";
		uart1 = "/serial@fe650000";
		uart2 = "/serial@fe660000";
		uart3 = "/serial@fe670000";
		uart4 = "/serial@fe680000";
		uart5 = "/serial@fe690000";
		uart6 = "/serial@fe6a0000";
		uart7 = "/serial@fe6b0000";
		uart8 = "/serial@fe6c0000";
		uart9 = "/serial@fe6d0000";
		thermal_zones = "/thermal-zones";
		cpu_thermal = "/thermal-zones/cpu-thermal";
		cpu_alert0 = "/thermal-zones/cpu-thermal/trips/cpu_alert0";
		cpu_alert1 = "/thermal-zones/cpu-thermal/trips/cpu_alert1";
		cpu_crit = "/thermal-zones/cpu-thermal/trips/cpu_crit";
		gpu_thermal = "/thermal-zones/gpu-thermal";
		tsadc = "/tsadc@fe710000";
		saradc = "/saradc@fe720000";
		pwm4 = "/pwm@fe6e0000";
		pwm5 = "/pwm@fe6e0010";
		pwm6 = "/pwm@fe6e0020";
		pwm7 = "/pwm@fe6e0030";
		pwm8 = "/pwm@fe6f0000";
		pwm9 = "/pwm@fe6f0010";
		pwm10 = "/pwm@fe6f0020";
		pwm11 = "/pwm@fe6f0030";
		pwm12 = "/pwm@fe700000";
		pwm13 = "/pwm@fe700010";
		pwm14 = "/pwm@fe700020";
		pwm15 = "/pwm@fe700030";
		pinctrl = "/pinctrl";
		gpio0 = "/pinctrl/gpio@fdd60000";
		gpio1 = "/pinctrl/gpio@fe740000";
		gpio2 = "/pinctrl/gpio@fe750000";
		gpio3 = "/pinctrl/gpio@fe760000";
		gpio4 = "/pinctrl/gpio@fe770000";
		pcfg_pull_up = "/pinctrl/pcfg-pull-up";
		pcfg_pull_down = "/pinctrl/pcfg-pull-down";
		pcfg_pull_none = "/pinctrl/pcfg-pull-none";
		pcfg_pull_none_drv_level_0 = "/pinctrl/pcfg-pull-none-drv-level-0";
		pcfg_pull_none_drv_level_1 = "/pinctrl/pcfg-pull-none-drv-level-1";
		pcfg_pull_none_drv_level_2 = "/pinctrl/pcfg-pull-none-drv-level-2";
		pcfg_pull_none_drv_level_3 = "/pinctrl/pcfg-pull-none-drv-level-3";
		pcfg_pull_none_drv_level_4 = "/pinctrl/pcfg-pull-none-drv-level-4";
		pcfg_pull_none_drv_level_5 = "/pinctrl/pcfg-pull-none-drv-level-5";
		pcfg_pull_none_drv_level_6 = "/pinctrl/pcfg-pull-none-drv-level-6";
		pcfg_pull_none_drv_level_7 = "/pinctrl/pcfg-pull-none-drv-level-7";
		pcfg_pull_none_drv_level_8 = "/pinctrl/pcfg-pull-none-drv-level-8";
		pcfg_pull_none_drv_level_9 = "/pinctrl/pcfg-pull-none-drv-level-9";
		pcfg_pull_none_drv_level_10 = "/pinctrl/pcfg-pull-none-drv-level-10";
		pcfg_pull_none_drv_level_11 = "/pinctrl/pcfg-pull-none-drv-level-11";
		pcfg_pull_none_drv_level_12 = "/pinctrl/pcfg-pull-none-drv-level-12";
		pcfg_pull_none_drv_level_13 = "/pinctrl/pcfg-pull-none-drv-level-13";
		pcfg_pull_none_drv_level_14 = "/pinctrl/pcfg-pull-none-drv-level-14";
		pcfg_pull_none_drv_level_15 = "/pinctrl/pcfg-pull-none-drv-level-15";
		pcfg_pull_up_drv_level_0 = "/pinctrl/pcfg-pull-up-drv-level-0";
		pcfg_pull_up_drv_level_1 = "/pinctrl/pcfg-pull-up-drv-level-1";
		pcfg_pull_up_drv_level_2 = "/pinctrl/pcfg-pull-up-drv-level-2";
		pcfg_pull_up_drv_level_3 = "/pinctrl/pcfg-pull-up-drv-level-3";
		pcfg_pull_up_drv_level_4 = "/pinctrl/pcfg-pull-up-drv-level-4";
		pcfg_pull_up_drv_level_5 = "/pinctrl/pcfg-pull-up-drv-level-5";
		pcfg_pull_up_drv_level_6 = "/pinctrl/pcfg-pull-up-drv-level-6";
		pcfg_pull_up_drv_level_7 = "/pinctrl/pcfg-pull-up-drv-level-7";
		pcfg_pull_up_drv_level_8 = "/pinctrl/pcfg-pull-up-drv-level-8";
		pcfg_pull_up_drv_level_9 = "/pinctrl/pcfg-pull-up-drv-level-9";
		pcfg_pull_up_drv_level_10 = "/pinctrl/pcfg-pull-up-drv-level-10";
		pcfg_pull_up_drv_level_11 = "/pinctrl/pcfg-pull-up-drv-level-11";
		pcfg_pull_up_drv_level_12 = "/pinctrl/pcfg-pull-up-drv-level-12";
		pcfg_pull_up_drv_level_13 = "/pinctrl/pcfg-pull-up-drv-level-13";
		pcfg_pull_up_drv_level_14 = "/pinctrl/pcfg-pull-up-drv-level-14";
		pcfg_pull_up_drv_level_15 = "/pinctrl/pcfg-pull-up-drv-level-15";
		pcfg_pull_down_drv_level_0 = "/pinctrl/pcfg-pull-down-drv-level-0";
		pcfg_pull_down_drv_level_1 = "/pinctrl/pcfg-pull-down-drv-level-1";
		pcfg_pull_down_drv_level_2 = "/pinctrl/pcfg-pull-down-drv-level-2";
		pcfg_pull_down_drv_level_3 = "/pinctrl/pcfg-pull-down-drv-level-3";
		pcfg_pull_down_drv_level_4 = "/pinctrl/pcfg-pull-down-drv-level-4";
		pcfg_pull_down_drv_level_5 = "/pinctrl/pcfg-pull-down-drv-level-5";
		pcfg_pull_down_drv_level_6 = "/pinctrl/pcfg-pull-down-drv-level-6";
		pcfg_pull_down_drv_level_7 = "/pinctrl/pcfg-pull-down-drv-level-7";
		pcfg_pull_down_drv_level_8 = "/pinctrl/pcfg-pull-down-drv-level-8";
		pcfg_pull_down_drv_level_9 = "/pinctrl/pcfg-pull-down-drv-level-9";
		pcfg_pull_down_drv_level_10 = "/pinctrl/pcfg-pull-down-drv-level-10";
		pcfg_pull_down_drv_level_11 = "/pinctrl/pcfg-pull-down-drv-level-11";
		pcfg_pull_down_drv_level_12 = "/pinctrl/pcfg-pull-down-drv-level-12";
		pcfg_pull_down_drv_level_13 = "/pinctrl/pcfg-pull-down-drv-level-13";
		pcfg_pull_down_drv_level_14 = "/pinctrl/pcfg-pull-down-drv-level-14";
		pcfg_pull_down_drv_level_15 = "/pinctrl/pcfg-pull-down-drv-level-15";
		pcfg_pull_up_smt = "/pinctrl/pcfg-pull-up-smt";
		pcfg_pull_down_smt = "/pinctrl/pcfg-pull-down-smt";
		pcfg_pull_none_smt = "/pinctrl/pcfg-pull-none-smt";
		pcfg_pull_none_drv_level_0_smt = "/pinctrl/pcfg-pull-none-drv-level-0-smt";
		pcfg_output_high = "/pinctrl/pcfg-output-high";
		pcfg_output_low = "/pinctrl/pcfg-output-low";
		acodec_pins = "/pinctrl/acodec/acodec-pins";
		audiopwm_lout = "/pinctrl/audiopwm/audiopwm-lout";
		audiopwm_loutn = "/pinctrl/audiopwm/audiopwm-loutn";
		audiopwm_loutp = "/pinctrl/audiopwm/audiopwm-loutp";
		audiopwm_rout = "/pinctrl/audiopwm/audiopwm-rout";
		audiopwm_routn = "/pinctrl/audiopwm/audiopwm-routn";
		audiopwm_routp = "/pinctrl/audiopwm/audiopwm-routp";
		bt656m0_pins = "/pinctrl/bt656/bt656m0-pins";
		bt656m1_pins = "/pinctrl/bt656/bt656m1-pins";
		bt1120_pins = "/pinctrl/bt1120/bt1120-pins";
		cam_clkout0 = "/pinctrl/cam/cam-clkout0";
		cam_clkout1 = "/pinctrl/cam/cam-clkout1";
		can0m0_pins = "/pinctrl/can0/can0m0-pins";
		can0m1_pins = "/pinctrl/can0/can0m1-pins";
		can1m0_pins = "/pinctrl/can1/can1m0-pins";
		can1m1_pins = "/pinctrl/can1/can1m1-pins";
		can2m0_pins = "/pinctrl/can2/can2m0-pins";
		can2m1_pins = "/pinctrl/can2/can2m1-pins";
		cif_clk = "/pinctrl/cif/cif-clk";
		cif_dvp_clk = "/pinctrl/cif/cif-dvp-clk";
		cif_dvp_bus16 = "/pinctrl/cif/cif-dvp-bus16";
		cif_dvp_bus8 = "/pinctrl/cif/cif-dvp-bus8";
		clk32k_in = "/pinctrl/clk32k/clk32k-in";
		clk32k_out0 = "/pinctrl/clk32k/clk32k-out0";
		clk32k_out1 = "/pinctrl/clk32k/clk32k-out1";
		cpu_pins = "/pinctrl/cpu/cpu-pins";
		ebc_extern = "/pinctrl/ebc/ebc-extern";
		ebc_pins = "/pinctrl/ebc/ebc-pins";
		edpdpm0_pins = "/pinctrl/edpdp/edpdpm0-pins";
		edpdpm1_pins = "/pinctrl/edpdp/edpdpm1-pins";
		emmc_rstnout = "/pinctrl/emmc/emmc-rstnout";
		emmc_bus8 = "/pinctrl/emmc/emmc-bus8";
		emmc_clk = "/pinctrl/emmc/emmc-clk";
		emmc_cmd = "/pinctrl/emmc/emmc-cmd";
		emmc_datastrobe = "/pinctrl/emmc/emmc-datastrobe";
		eth0_pins = "/pinctrl/eth0/eth0-pins";
		eth1m0_pins = "/pinctrl/eth1/eth1m0-pins";
		eth1m1_pins = "/pinctrl/eth1/eth1m1-pins";
		flash_pins = "/pinctrl/flash/flash-pins";
		fspi_pins = "/pinctrl/fspi/fspi-pins";
		fspi_cs1 = "/pinctrl/fspi/fspi-cs1";
		gmac0_miim = "/pinctrl/gmac0/gmac0-miim";
		gmac0_clkinout = "/pinctrl/gmac0/gmac0-clkinout";
		gmac0_rx_er = "/pinctrl/gmac0/gmac0-rx-er";
		gmac0_rx_bus2 = "/pinctrl/gmac0/gmac0-rx-bus2";
		gmac0_tx_bus2 = "/pinctrl/gmac0/gmac0-tx-bus2";
		gmac0_rgmii_clk = "/pinctrl/gmac0/gmac0-rgmii-clk";
		gmac0_rgmii_bus = "/pinctrl/gmac0/gmac0-rgmii-bus";
		gmac1m0_miim = "/pinctrl/gmac1/gmac1m0-miim";
		gmac1m0_clkinout = "/pinctrl/gmac1/gmac1m0-clkinout";
		gmac1m0_rx_er = "/pinctrl/gmac1/gmac1m0-rx-er";
		gmac1m0_rx_bus2 = "/pinctrl/gmac1/gmac1m0-rx-bus2";
		gmac1m0_tx_bus2 = "/pinctrl/gmac1/gmac1m0-tx-bus2";
		gmac1m0_rgmii_clk = "/pinctrl/gmac1/gmac1m0-rgmii-clk";
		gmac1m0_rgmii_bus = "/pinctrl/gmac1/gmac1m0-rgmii-bus";
		gmac1m1_miim = "/pinctrl/gmac1/gmac1m1-miim";
		gmac1m1_clkinout = "/pinctrl/gmac1/gmac1m1-clkinout";
		gmac1m1_rx_er = "/pinctrl/gmac1/gmac1m1-rx-er";
		gmac1m1_rx_bus2 = "/pinctrl/gmac1/gmac1m1-rx-bus2";
		gmac1m1_tx_bus2 = "/pinctrl/gmac1/gmac1m1-tx-bus2";
		gmac1m1_rgmii_clk = "/pinctrl/gmac1/gmac1m1-rgmii-clk";
		gmac1m1_rgmii_bus = "/pinctrl/gmac1/gmac1m1-rgmii-bus";
		gpu_pins = "/pinctrl/gpu/gpu-pins";
		hdmitxm0_cec = "/pinctrl/hdmitx/hdmitxm0-cec";
		hdmitxm1_cec = "/pinctrl/hdmitx/hdmitxm1-cec";
		hdmitx_scl = "/pinctrl/hdmitx/hdmitx-scl";
		hdmitx_sda = "/pinctrl/hdmitx/hdmitx-sda";
		i2c0_xfer = "/pinctrl/i2c0/i2c0-xfer";
		i2c1_xfer = "/pinctrl/i2c1/i2c1-xfer";
		i2c2m0_xfer = "/pinctrl/i2c2/i2c2m0-xfer";
		i2c2m1_xfer = "/pinctrl/i2c2/i2c2m1-xfer";
		i2c3m0_xfer = "/pinctrl/i2c3/i2c3m0-xfer";
		i2c3m1_xfer = "/pinctrl/i2c3/i2c3m1-xfer";
		i2c4m0_xfer = "/pinctrl/i2c4/i2c4m0-xfer";
		i2c4m1_xfer = "/pinctrl/i2c4/i2c4m1-xfer";
		i2c5m0_xfer = "/pinctrl/i2c5/i2c5m0-xfer";
		i2c5m1_xfer = "/pinctrl/i2c5/i2c5m1-xfer";
		i2s1m0_lrckrx = "/pinctrl/i2s1/i2s1m0-lrckrx";
		i2s1m0_lrcktx = "/pinctrl/i2s1/i2s1m0-lrcktx";
		i2s1m0_mclk = "/pinctrl/i2s1/i2s1m0-mclk";
		i2s1m0_sclkrx = "/pinctrl/i2s1/i2s1m0-sclkrx";
		i2s1m0_sclktx = "/pinctrl/i2s1/i2s1m0-sclktx";
		i2s1m0_sdi0 = "/pinctrl/i2s1/i2s1m0-sdi0";
		i2s1m0_sdi1 = "/pinctrl/i2s1/i2s1m0-sdi1";
		i2s1m0_sdi2 = "/pinctrl/i2s1/i2s1m0-sdi2";
		i2s1m0_sdi3 = "/pinctrl/i2s1/i2s1m0-sdi3";
		i2s1m0_sdo0 = "/pinctrl/i2s1/i2s1m0-sdo0";
		i2s1m0_sdo1 = "/pinctrl/i2s1/i2s1m0-sdo1";
		i2s1m0_sdo2 = "/pinctrl/i2s1/i2s1m0-sdo2";
		i2s1m0_sdo3 = "/pinctrl/i2s1/i2s1m0-sdo3";
		i2s1m1_lrckrx = "/pinctrl/i2s1/i2s1m1-lrckrx";
		i2s1m1_lrcktx = "/pinctrl/i2s1/i2s1m1-lrcktx";
		i2s1m1_mclk = "/pinctrl/i2s1/i2s1m1-mclk";
		i2s1m1_sclkrx = "/pinctrl/i2s1/i2s1m1-sclkrx";
		i2s1m1_sclktx = "/pinctrl/i2s1/i2s1m1-sclktx";
		i2s1m1_sdi0 = "/pinctrl/i2s1/i2s1m1-sdi0";
		i2s1m1_sdi1 = "/pinctrl/i2s1/i2s1m1-sdi1";
		i2s1m1_sdi2 = "/pinctrl/i2s1/i2s1m1-sdi2";
		i2s1m1_sdi3 = "/pinctrl/i2s1/i2s1m1-sdi3";
		i2s1m1_sdo0 = "/pinctrl/i2s1/i2s1m1-sdo0";
		i2s1m1_sdo1 = "/pinctrl/i2s1/i2s1m1-sdo1";
		i2s1m1_sdo2 = "/pinctrl/i2s1/i2s1m1-sdo2";
		i2s1m1_sdo3 = "/pinctrl/i2s1/i2s1m1-sdo3";
		i2s1m2_lrckrx = "/pinctrl/i2s1/i2s1m2-lrckrx";
		i2s1m2_lrcktx = "/pinctrl/i2s1/i2s1m2-lrcktx";
		i2s1m2_mclk = "/pinctrl/i2s1/i2s1m2-mclk";
		i2s1m2_sclkrx = "/pinctrl/i2s1/i2s1m2-sclkrx";
		i2s1m2_sclktx = "/pinctrl/i2s1/i2s1m2-sclktx";
		i2s1m2_sdi0 = "/pinctrl/i2s1/i2s1m2-sdi0";
		i2s1m2_sdi1 = "/pinctrl/i2s1/i2s1m2-sdi1";
		i2s1m2_sdi2 = "/pinctrl/i2s1/i2s1m2-sdi2";
		i2s1m2_sdi3 = "/pinctrl/i2s1/i2s1m2-sdi3";
		i2s1m2_sdo0 = "/pinctrl/i2s1/i2s1m2-sdo0";
		i2s1m2_sdo1 = "/pinctrl/i2s1/i2s1m2-sdo1";
		i2s1m2_sdo2 = "/pinctrl/i2s1/i2s1m2-sdo2";
		i2s1m2_sdo3 = "/pinctrl/i2s1/i2s1m2-sdo3";
		i2s2m0_lrckrx = "/pinctrl/i2s2/i2s2m0-lrckrx";
		i2s2m0_lrcktx = "/pinctrl/i2s2/i2s2m0-lrcktx";
		i2s2m0_mclk = "/pinctrl/i2s2/i2s2m0-mclk";
		i2s2m0_sclkrx = "/pinctrl/i2s2/i2s2m0-sclkrx";
		i2s2m0_sclktx = "/pinctrl/i2s2/i2s2m0-sclktx";
		i2s2m0_sdi = "/pinctrl/i2s2/i2s2m0-sdi";
		i2s2m0_sdo = "/pinctrl/i2s2/i2s2m0-sdo";
		i2s2m1_lrckrx = "/pinctrl/i2s2/i2s2m1-lrckrx";
		i2s2m1_lrcktx = "/pinctrl/i2s2/i2s2m1-lrcktx";
		i2s2m1_mclk = "/pinctrl/i2s2/i2s2m1-mclk";
		i2s2m1_sclkrx = "/pinctrl/i2s2/i2s2m1-sclkrx";
		i2s2m1_sclktx = "/pinctrl/i2s2/i2s2m1-sclktx";
		i2s2m1_sdi = "/pinctrl/i2s2/i2s2m1-sdi";
		i2s2m1_sdo = "/pinctrl/i2s2/i2s2m1-sdo";
		i2s3m0_lrck = "/pinctrl/i2s3/i2s3m0-lrck";
		i2s3m0_mclk = "/pinctrl/i2s3/i2s3m0-mclk";
		i2s3m0_sclk = "/pinctrl/i2s3/i2s3m0-sclk";
		i2s3m0_sdi = "/pinctrl/i2s3/i2s3m0-sdi";
		i2s3m0_sdo = "/pinctrl/i2s3/i2s3m0-sdo";
		i2s3m1_lrck = "/pinctrl/i2s3/i2s3m1-lrck";
		i2s3m1_mclk = "/pinctrl/i2s3/i2s3m1-mclk";
		i2s3m1_sclk = "/pinctrl/i2s3/i2s3m1-sclk";
		i2s3m1_sdi = "/pinctrl/i2s3/i2s3m1-sdi";
		i2s3m1_sdo = "/pinctrl/i2s3/i2s3m1-sdo";
		isp_pins = "/pinctrl/isp/isp-pins";
		jtag_pins = "/pinctrl/jtag/jtag-pins";
		lcdc_ctl = "/pinctrl/lcdc/lcdc-ctl";
		mcu_pins = "/pinctrl/mcu/mcu-pins";
		npu_pins = "/pinctrl/npu/npu-pins";
		pcie20m0_pins = "/pinctrl/pcie20/pcie20m0-pins";
		pcie20m1_pins = "/pinctrl/pcie20/pcie20m1-pins";
		pcie20m2_pins = "/pinctrl/pcie20/pcie20m2-pins";
		pcie20_buttonrstn = "/pinctrl/pcie20/pcie20-buttonrstn";
		pcie30x1m0_pins = "/pinctrl/pcie30x1/pcie30x1m0-pins";
		pcie30x1m1_pins = "/pinctrl/pcie30x1/pcie30x1m1-pins";
		pcie30x1m2_pins = "/pinctrl/pcie30x1/pcie30x1m2-pins";
		pcie30x1_buttonrstn = "/pinctrl/pcie30x1/pcie30x1-buttonrstn";
		pcie30x2m0_pins = "/pinctrl/pcie30x2/pcie30x2m0-pins";
		pcie30x2m1_pins = "/pinctrl/pcie30x2/pcie30x2m1-pins";
		pcie30x2m2_pins = "/pinctrl/pcie30x2/pcie30x2m2-pins";
		pcie30x2_buttonrstn = "/pinctrl/pcie30x2/pcie30x2-buttonrstn";
		pdmm0_clk = "/pinctrl/pdm/pdmm0-clk";
		pdmm0_clk1 = "/pinctrl/pdm/pdmm0-clk1";
		pdmm0_sdi0 = "/pinctrl/pdm/pdmm0-sdi0";
		pdmm0_sdi1 = "/pinctrl/pdm/pdmm0-sdi1";
		pdmm0_sdi2 = "/pinctrl/pdm/pdmm0-sdi2";
		pdmm0_sdi3 = "/pinctrl/pdm/pdmm0-sdi3";
		pdmm1_clk = "/pinctrl/pdm/pdmm1-clk";
		pdmm1_clk1 = "/pinctrl/pdm/pdmm1-clk1";
		pdmm1_sdi0 = "/pinctrl/pdm/pdmm1-sdi0";
		pdmm1_sdi1 = "/pinctrl/pdm/pdmm1-sdi1";
		pdmm1_sdi2 = "/pinctrl/pdm/pdmm1-sdi2";
		pdmm1_sdi3 = "/pinctrl/pdm/pdmm1-sdi3";
		pdmm2_clk1 = "/pinctrl/pdm/pdmm2-clk1";
		pdmm2_sdi0 = "/pinctrl/pdm/pdmm2-sdi0";
		pdmm2_sdi1 = "/pinctrl/pdm/pdmm2-sdi1";
		pdmm2_sdi2 = "/pinctrl/pdm/pdmm2-sdi2";
		pdmm2_sdi3 = "/pinctrl/pdm/pdmm2-sdi3";
		pmic_pins = "/pinctrl/pmic/pmic-pins";
		pmic_int = "/pinctrl/pmic/pmic_int";
		pmu_pins = "/pinctrl/pmu/pmu-pins";
		pwm0m0_pins = "/pinctrl/pwm0/pwm0m0-pins";
		pwm0m1_pins = "/pinctrl/pwm0/pwm0m1-pins";
		pwm1m0_pins = "/pinctrl/pwm1/pwm1m0-pins";
		pwm1m1_pins = "/pinctrl/pwm1/pwm1m1-pins";
		pwm2m0_pins = "/pinctrl/pwm2/pwm2m0-pins";
		pwm2m1_pins = "/pinctrl/pwm2/pwm2m1-pins";
		pwm3_pins = "/pinctrl/pwm3/pwm3-pins";
		pwm4_pins = "/pinctrl/pwm4/pwm4-pins";
		pwm5_pins = "/pinctrl/pwm5/pwm5-pins";
		pwm6_pins = "/pinctrl/pwm6/pwm6-pins";
		pwm7_pins = "/pinctrl/pwm7/pwm7-pins";
		pwm8m0_pins = "/pinctrl/pwm8/pwm8m0-pins";
		pwm8m1_pins = "/pinctrl/pwm8/pwm8m1-pins";
		pwm9m0_pins = "/pinctrl/pwm9/pwm9m0-pins";
		pwm9m1_pins = "/pinctrl/pwm9/pwm9m1-pins";
		pwm10m0_pins = "/pinctrl/pwm10/pwm10m0-pins";
		pwm10m1_pins = "/pinctrl/pwm10/pwm10m1-pins";
		pwm11m0_pins = "/pinctrl/pwm11/pwm11m0-pins";
		pwm11m1_pins = "/pinctrl/pwm11/pwm11m1-pins";
		pwm12m0_pins = "/pinctrl/pwm12/pwm12m0-pins";
		pwm12m1_pins = "/pinctrl/pwm12/pwm12m1-pins";
		pwm13m0_pins = "/pinctrl/pwm13/pwm13m0-pins";
		pwm13m1_pins = "/pinctrl/pwm13/pwm13m1-pins";
		pwm14m0_pins = "/pinctrl/pwm14/pwm14m0-pins";
		pwm14m1_pins = "/pinctrl/pwm14/pwm14m1-pins";
		pwm15m0_pins = "/pinctrl/pwm15/pwm15m0-pins";
		pwm15m1_pins = "/pinctrl/pwm15/pwm15m1-pins";
		refclk_pins = "/pinctrl/refclk/refclk-pins";
		sata_pins = "/pinctrl/sata/sata-pins";
		sata0_pins = "/pinctrl/sata0/sata0-pins";
		sata1_pins = "/pinctrl/sata1/sata1-pins";
		sata2_pins = "/pinctrl/sata2/sata2-pins";
		scr_pins = "/pinctrl/scr/scr-pins";
		sdmmc0_bus4 = "/pinctrl/sdmmc0/sdmmc0-bus4";
		sdmmc0_clk = "/pinctrl/sdmmc0/sdmmc0-clk";
		sdmmc0_cmd = "/pinctrl/sdmmc0/sdmmc0-cmd";
		sdmmc0_det = "/pinctrl/sdmmc0/sdmmc0-det";
		sdmmc0_pwren = "/pinctrl/sdmmc0/sdmmc0-pwren";
		sdmmc1_bus4 = "/pinctrl/sdmmc1/sdmmc1-bus4";
		sdmmc1_clk = "/pinctrl/sdmmc1/sdmmc1-clk";
		sdmmc1_cmd = "/pinctrl/sdmmc1/sdmmc1-cmd";
		sdmmc1_det = "/pinctrl/sdmmc1/sdmmc1-det";
		sdmmc1_pwren = "/pinctrl/sdmmc1/sdmmc1-pwren";
		sdmmc2m0_bus4 = "/pinctrl/sdmmc2/sdmmc2m0-bus4";
		sdmmc2m0_clk = "/pinctrl/sdmmc2/sdmmc2m0-clk";
		sdmmc2m0_cmd = "/pinctrl/sdmmc2/sdmmc2m0-cmd";
		sdmmc2m0_det = "/pinctrl/sdmmc2/sdmmc2m0-det";
		sdmmc2m0_pwren = "/pinctrl/sdmmc2/sdmmc2m0-pwren";
		sdmmc2m1_bus4 = "/pinctrl/sdmmc2/sdmmc2m1-bus4";
		sdmmc2m1_clk = "/pinctrl/sdmmc2/sdmmc2m1-clk";
		sdmmc2m1_cmd = "/pinctrl/sdmmc2/sdmmc2m1-cmd";
		sdmmc2m1_det = "/pinctrl/sdmmc2/sdmmc2m1-det";
		sdmmc2m1_pwren = "/pinctrl/sdmmc2/sdmmc2m1-pwren";
		spdifm0_tx = "/pinctrl/spdif/spdifm0-tx";
		spdifm1_tx = "/pinctrl/spdif/spdifm1-tx";
		spdifm2_tx = "/pinctrl/spdif/spdifm2-tx";
		spi0m0_pins = "/pinctrl/spi0/spi0m0-pins";
		spi0m0_cs0 = "/pinctrl/spi0/spi0m0-cs0";
		spi0m0_cs1 = "/pinctrl/spi0/spi0m0-cs1";
		spi0m1_pins = "/pinctrl/spi0/spi0m1-pins";
		spi0m1_cs0 = "/pinctrl/spi0/spi0m1-cs0";
		spi1m0_pins = "/pinctrl/spi1/spi1m0-pins";
		spi1m0_cs0 = "/pinctrl/spi1/spi1m0-cs0";
		spi1m0_cs1 = "/pinctrl/spi1/spi1m0-cs1";
		spi1m1_pins = "/pinctrl/spi1/spi1m1-pins";
		spi1m1_cs0 = "/pinctrl/spi1/spi1m1-cs0";
		spi2m0_pins = "/pinctrl/spi2/spi2m0-pins";
		spi2m0_cs0 = "/pinctrl/spi2/spi2m0-cs0";
		spi2m0_cs1 = "/pinctrl/spi2/spi2m0-cs1";
		spi2m1_pins = "/pinctrl/spi2/spi2m1-pins";
		spi2m1_cs0 = "/pinctrl/spi2/spi2m1-cs0";
		spi2m1_cs1 = "/pinctrl/spi2/spi2m1-cs1";
		spi3m0_pins = "/pinctrl/spi3/spi3m0-pins";
		spi3m0_cs0 = "/pinctrl/spi3/spi3m0-cs0";
		spi3m0_cs1 = "/pinctrl/spi3/spi3m0-cs1";
		spi3m1_pins = "/pinctrl/spi3/spi3m1-pins";
		spi3m1_cs0 = "/pinctrl/spi3/spi3m1-cs0";
		spi3m1_cs1 = "/pinctrl/spi3/spi3m1-cs1";
		tsadcm0_shut = "/pinctrl/tsadc/tsadcm0-shut";
		tsadcm1_shut = "/pinctrl/tsadc/tsadcm1-shut";
		tsadc_shutorg = "/pinctrl/tsadc/tsadc-shutorg";
		tsadc_pin = "/pinctrl/tsadc/tsadc-pin";
		uart0_xfer = "/pinctrl/uart0/uart0-xfer";
		uart0_ctsn = "/pinctrl/uart0/uart0-ctsn";
		uart0_rtsn = "/pinctrl/uart0/uart0-rtsn";
		uart1m0_xfer = "/pinctrl/uart1/uart1m0-xfer";
		uart1m0_ctsn = "/pinctrl/uart1/uart1m0-ctsn";
		uart1m0_rtsn = "/pinctrl/uart1/uart1m0-rtsn";
		uart1m1_xfer = "/pinctrl/uart1/uart1m1-xfer";
		uart1m1_ctsn = "/pinctrl/uart1/uart1m1-ctsn";
		uart1m1_rtsn = "/pinctrl/uart1/uart1m1-rtsn";
		uart2m0_xfer = "/pinctrl/uart2/uart2m0-xfer";
		uart2m1_xfer = "/pinctrl/uart2/uart2m1-xfer";
		uart3m0_xfer = "/pinctrl/uart3/uart3m0-xfer";
		uart3m0_ctsn = "/pinctrl/uart3/uart3m0-ctsn";
		uart3m0_rtsn = "/pinctrl/uart3/uart3m0-rtsn";
		uart3m1_xfer = "/pinctrl/uart3/uart3m1-xfer";
		uart4m0_xfer = "/pinctrl/uart4/uart4m0-xfer";
		uart4m0_ctsn = "/pinctrl/uart4/uart4m0-ctsn";
		uart4m0_rtsn = "/pinctrl/uart4/uart4m0-rtsn";
		uart4m1_xfer = "/pinctrl/uart4/uart4m1-xfer";
		uart5m0_xfer = "/pinctrl/uart5/uart5m0-xfer";
		uart5m0_ctsn = "/pinctrl/uart5/uart5m0-ctsn";
		uart5m0_rtsn = "/pinctrl/uart5/uart5m0-rtsn";
		uart5m1_xfer = "/pinctrl/uart5/uart5m1-xfer";
		uart6m0_xfer = "/pinctrl/uart6/uart6m0-xfer";
		uart6m0_ctsn = "/pinctrl/uart6/uart6m0-ctsn";
		uart6m0_rtsn = "/pinctrl/uart6/uart6m0-rtsn";
		uart6m1_xfer = "/pinctrl/uart6/uart6m1-xfer";
		uart7m0_xfer = "/pinctrl/uart7/uart7m0-xfer";
		uart7m0_ctsn = "/pinctrl/uart7/uart7m0-ctsn";
		uart7m0_rtsn = "/pinctrl/uart7/uart7m0-rtsn";
		uart7m1_xfer = "/pinctrl/uart7/uart7m1-xfer";
		uart7m2_xfer = "/pinctrl/uart7/uart7m2-xfer";
		uart8m0_xfer = "/pinctrl/uart8/uart8m0-xfer";
		uart8m0_ctsn = "/pinctrl/uart8/uart8m0-ctsn";
		uart8m0_rtsn = "/pinctrl/uart8/uart8m0-rtsn";
		uart8m1_xfer = "/pinctrl/uart8/uart8m1-xfer";
		uart9m0_xfer = "/pinctrl/uart9/uart9m0-xfer";
		uart9m0_ctsn = "/pinctrl/uart9/uart9m0-ctsn";
		uart9m0_rtsn = "/pinctrl/uart9/uart9m0-rtsn";
		uart9m1_xfer = "/pinctrl/uart9/uart9m1-xfer";
		uart9m2_xfer = "/pinctrl/uart9/uart9m2-xfer";
		vopm0_pins = "/pinctrl/vop/vopm0-pins";
		vopm1_pins = "/pinctrl/vop/vopm1-pins";
		spi0m0_pins_hs = "/pinctrl/spi0-hs/spi0m0-pins";
		spi0m0_cs0_hs = "/pinctrl/spi0-hs/spi0m0-cs0";
		spi0m0_cs1_hs = "/pinctrl/spi0-hs/spi0m0-cs1";
		spi0m1_pins_hs = "/pinctrl/spi0-hs/spi0m1-pins";
		spi0m1_cs0_hs = "/pinctrl/spi0-hs/spi0m1-cs0";
		spi1m0_pins_hs = "/pinctrl/spi1-hs/spi1m0-pins";
		spi1m0_cs0_hs = "/pinctrl/spi1-hs/spi1m0-cs0";
		spi1m0_cs1_hs = "/pinctrl/spi1-hs/spi1m0-cs1";
		spi1m1_pins_hs = "/pinctrl/spi1-hs/spi1m1-pins";
		spi1m1_cs0_hs = "/pinctrl/spi1-hs/spi1m1-cs0";
		spi2m0_pins_hs = "/pinctrl/spi2-hs/spi2m0-pins";
		spi2m0_cs0_hs = "/pinctrl/spi2-hs/spi2m0-cs0";
		spi2m0_cs1_hs = "/pinctrl/spi2-hs/spi2m0-cs1";
		spi2m1_pins_hs = "/pinctrl/spi2-hs/spi2m1-pins";
		spi2m1_cs0_hs = "/pinctrl/spi2-hs/spi2m1-cs0";
		spi2m1_cs1_hs = "/pinctrl/spi2-hs/spi2m1-cs1";
		spi3m0_pins_hs = "/pinctrl/spi3-hs/spi3m0-pins";
		spi3m0_cs0_hs = "/pinctrl/spi3-hs/spi3m0-cs0";
		spi3m0_cs1_hs = "/pinctrl/spi3-hs/spi3m0-cs1";
		spi3m1_pins_hs = "/pinctrl/spi3-hs/spi3m1-pins";
		spi3m1_cs0_hs = "/pinctrl/spi3-hs/spi3m1-cs0";
		spi3m1_cs1_hs = "/pinctrl/spi3-hs/spi3m1-cs1";
		gmac0_tx_bus2_level3 = "/pinctrl/gmac-txd-level3/gmac0-tx-bus2-level3";
		gmac0_rgmii_bus_level3 = "/pinctrl/gmac-txd-level3/gmac0-rgmii-bus-level3";
		gmac1m0_tx_bus2_level3 = "/pinctrl/gmac-txd-level3/gmac1m0-tx-bus2-level3";
		gmac1m0_rgmii_bus_level3 = "/pinctrl/gmac-txd-level3/gmac1m0-rgmii-bus-level3";
		gmac1m1_tx_bus2_level3 = "/pinctrl/gmac-txd-level3/gmac1m1-tx-bus2-level3";
		gmac1m1_rgmii_bus_level3 = "/pinctrl/gmac-txd-level3/gmac1m1-rgmii-bus-level3";
		gmac0_rgmii_clk_level2 = "/pinctrl/gmac-txc-level2/gmac0-rgmii-clk-level2";
		gmac1m0_rgmii_clk_level2 = "/pinctrl/gmac-txc-level2/gmac1m0-rgmii-clk-level2";
		gmac1m1_rgmii_clk_level2 = "/pinctrl/gmac-txc-level2/gmac1m1-rgmii-clk-level2";
		qos_pcie3x1 = "/qos@fe190080";
		qos_pcie3x2 = "/qos@fe190100";
		qos_sata0 = "/qos@fe190200";
		gmac0 = "/ethernet@fe2a0000";
		mdio0 = "/ethernet@fe2a0000/mdio";
		rgmii_phy0 = "/ethernet@fe2a0000/mdio/ethernet-phy@0";
		gmac0_stmmac_axi_setup = "/ethernet@fe2a0000/stmmac-axi-config";
		gmac0_mtl_rx_setup = "/ethernet@fe2a0000/rx-queues-config";
		gmac0_mtl_tx_setup = "/ethernet@fe2a0000/tx-queues-config";
		chosen = "/chosen";
		dc_12v = "/dc-12v";
		vcc3v3_sys = "/vcc3v3-sys";
		vcc5v0_sys = "/vcc5v0-sys";
		vcc3v3_lcd0_n = "/vcc3v3-lcd0-n";
		vcc3v3_lcd1_n = "/vcc3v3-lcd1-n";
	};
};
